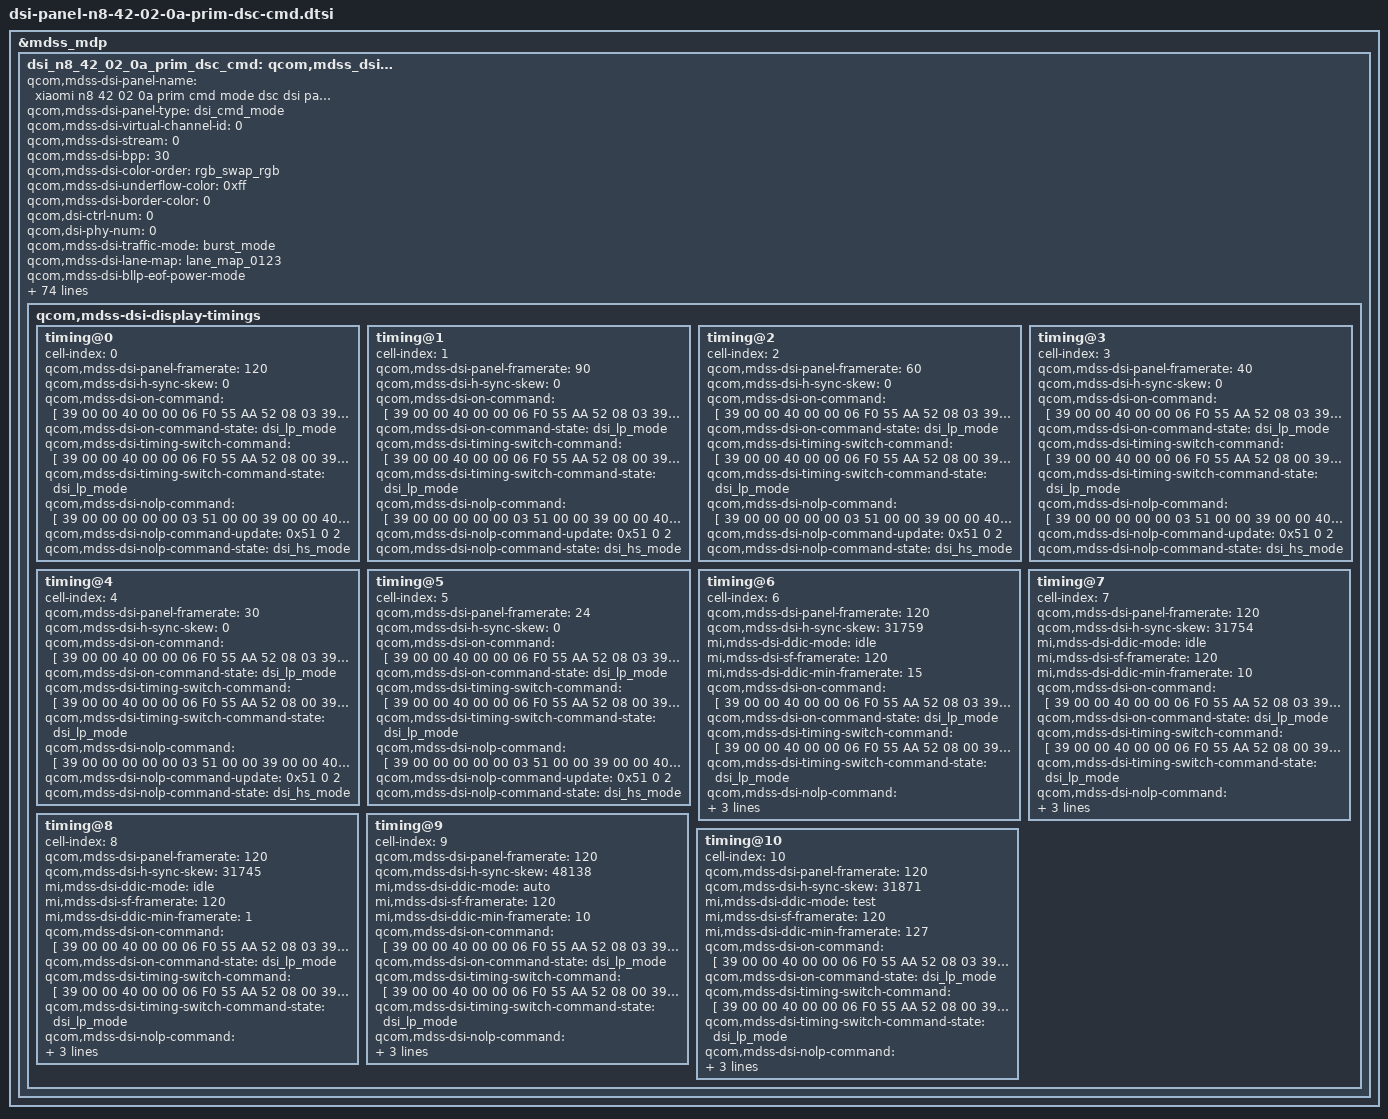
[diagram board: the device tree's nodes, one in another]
&mdss_mdp {
	dsi_n8_42_02_0a_prim_dsc_cmd: qcom,mdss_dsi_n8_42_02_0a_prim_dsc_cmd {
		qcom,mdss-dsi-panel-name = "xiaomi n8 42 02 0a prim cmd mode dsc dsi panel";
		qcom,mdss-dsi-panel-type = "dsi_cmd_mode";
		qcom,mdss-dsi-virtual-channel-id = <0>;
		qcom,mdss-dsi-stream = <0>;
		qcom,mdss-dsi-bpp = <30>;
		qcom,mdss-dsi-color-order = "rgb_swap_rgb";
		qcom,mdss-dsi-underflow-color = <0xff>;
		qcom,mdss-dsi-border-color = <0>;
		qcom,dsi-ctrl-num = <0>;
		qcom,dsi-phy-num = <0>;

		qcom,mdss-dsi-traffic-mode = "burst_mode";
		qcom,mdss-dsi-lane-map = "lane_map_0123";
		qcom,mdss-dsi-bllp-eof-power-mode;
		qcom,mdss-dsi-bllp-power-mode;
		qcom,mdss-dsi-lane-0-state;
		qcom,mdss-dsi-lane-1-state;
		qcom,mdss-dsi-lane-2-state;
		qcom,mdss-dsi-lane-3-state;
		qcom,mdss-dsi-dma-trigger = "trigger_sw";
		qcom,mdss-dsi-mdp-trigger = "none";
		qcom,mdss-dsi-reset-sequence = <1 1>, <0 1>, <1 10>;
		qcom,mdss-pan-physical-width-dimension = <675>;
		qcom,mdss-pan-physical-height-dimension = <1606>;
		qcom,mdss-dsi-te-pin-select = <1>;
		qcom,mdss-dsi-wr-mem-start = <0x2c>;
		qcom,mdss-dsi-wr-mem-continue = <0x3c>;
		qcom,mdss-dsi-te-dcs-command = <1>;
		qcom,mdss-dsi-te-check-enable;
		qcom,mdss-dsi-te-using-te-pin;
		qcom,mdss-dsi-tx-eot-append;
		qcom,mdss-dsi-lp11-init;

		qcom,mdss-dsi-bl-inverted-dbv;
		qcom,bl-update-flag = "delay_until_first_frame";

		qcom,mdss-dsi-panel-hdr-enabled;
		qcom,mdss-dsi-panel-hdr-color-primaries = <14500 15500 32000
			17000 15500 30000 8000 3000>;
		qcom,mdss-dsi-panel-peak-brightness = <4200000>;
		qcom,mdss-dsi-panel-blackness-level = <3230>;

		qcom,mdss-dsi-dma-schedule-line = <1>;
		qcom,mdss-dsi-dma-schedule-window = <50>;

		/* IRQF_ONESHOT | IRQF_TRIGGER_HEIGH */
		mi,esd-err-irq-gpio = <&tlmm 92 0x2004>;
		//qcom,spr-pack-type = "pentile";

		mi,panel-id = <0x00004E38 0x5042020A>;

		mi,ddic-round-corner-enabled;

		mi,flat-need-sync-te;
		mi,flatmode-default-on-enabled;

		mi,flatmode-status-check-enabled;
		mi,mdss-dsi-panel-flatmode-status-command = [
			06 01 00 01 00 00 01 5F
		];
		mi,mdss-dsi-panel-flatmode-status-command-state = "dsi_hs_mode";
		mi,mdss-dsi-panel-flatmode-status-read-length = <1>;
		mi,mdss-dsi-panel-flatmode-on-status-value = <0x00>;

		mi,mdss-dsi-panel-wp-read-command = [06 01 00 01 00 00 01 A3];
		mi,mdss-dsi-panel-wp-read-command-state = "dsi_hs_mode";
		mi,mdss-dsi-panel-wp-read-length = <8>;
		/* esd-check reg_read */
		//qcom,esd-check-enabled;
		//qcom,esd-aod-check-enabled;
		//mi,mdss-dsi-panel-status-check-interval = <1000>;
		//qcom,mdss-dsi-panel-status-check-mode = "reg_read";
		//mi,mdss-dsi-panel-status-offset-command = [39 00 00 00 00 00 03 FF 5A 82
		//					      39 00 00 00 00 00 02 65 01];
		//qcom,mdss-dsi-panel-status-command = [06 01 00 00 00 00 01 F9];
		//mi,mdss-dsi-panel-status-after-command = [39 00 00 00 00 00 03 FF 5A 00];
		//qcom,mdss-dsi-panel-status-command-state = "dsi_lp_mode";
		//mi,mdss-dsi-panel-status-offset-command-state = "dsi_lp_mode";
		//mi,mdss-dsi-panel-status-after-command-state = "dsi_lp_mode";
		//qcom,mdss-dsi-panel-status-value = <0x08>;
		//qcom,mdss-dsi-panel-status-read-length = <1>;

		mi,panel-on-dimming-delay = <120>;
		mi,max-brightness-clone = <16383>;

		mi,mdss-dsi-fac-bl-max-level = <11467>;
		mi,mdss-fac-brightness-max-level = <11467>;
		mi,doze-hbm-dbv-level = <1311>;
		mi,doze-lbm-dbv-level = <80>;

		qcom,mdss-dsi-display-timings {
			timing@0 {
				#include "dsi-panel-n8-42-02-0a-prim-dsc-cmd-common.dtsi"
				cell-index = <0>;
				qcom,mdss-dsi-panel-framerate = <120>;
				qcom,mdss-dsi-h-sync-skew = <0>;

				qcom,mdss-dsi-on-command = [
					/* Low frame switch skip 120 TE */
					39 00 00 40 00 00 06 F0 55 AA 52 08 03
					39 00 00 40 00 00 02 6F 0B
					39 00 00 00 00 00 02 C6 06
					/*IDLE 1*/
					39 00 00 40 00 00 06 F0 55 AA 52 08 00
					39 00 00 40 00 00 02 6F A4
					39 00 00 40 00 00 11 BA 03 03 03 06 01 01 01 06 00 01 01 14 00 00 01 16
					39 00 00 40 00 00 02 6F 1C
					39 00 00 40 00 00 11 BA 01 01 01 01 00 00 00 00 01 01 01 01 00 00 00 00
					39 00 00 40 00 00 02 6F 2C
					39 00 00 40 00 00 11 BA 01 01 01 01 01 01 01 01 01 01 01 01 00 00 00 00
					39 00 00 40 00 00 02 6F 3C
					39 00 00 40 00 00 11 BA 01 01 01 01 03 03 03 03 01 01 01 01 00 00 00 00
					39 00 00 40 00 00 02 6F 4C
					39 00 00 40 00 00 11 BA 01 01 01 01 0B 0B 04 0B 01 01 01 01 00 00 00 00
					/*thermal compensation DBI on*/
					39 00 00 40 00 00 06 F0 55 AA 52 08 08
					39 00 00 40 00 00 03 C2 22 80
					39 00 00 40 00 00 02 C7 13
					39 00 00 40 00 00 13 CB 00 00 00 00 00 00 00 00 00 00 00 00 00 00 00 00 00 00
					39 00 00 40 00 00 13 CC 00 00 00 00 00 00 00 00 00 00 00 00 00 00 00 00 00 00
					39 00 00 40 00 00 13 CE 00 00 00 00 00 00 00 00 00 00 00 00 00 00 00 00 00 00
					39 00 00 40 00 00 03 D3 80 01
					39 00 00 40 00 00 02 6F 02
					39 00 00 40 00 00 06 D3 10 00 98 00 6B
					39 00 00 00 00 00 05 67 80 40 80 80
					/*on ddic corner*/
					39 00 00 40 00 00 06 F0 55 AA 52 08 07
					39 00 00 40 00 00 02 6F 03
					39 00 00 40 00 00 05 C0 00 00 00 00
					39 00 00 40 00 00 16 C1 30 0F 02 71 09 61 F6 6E 3F FD BA F2 3F F9 AE 9E 00 00 89 54 40
					39 00 00 40 00 00 02 6F 15
					39 00 00 40 00 00 11 C1 0F 00 37 AF 00 00 19 37 F0 E7 89 0B 9F 30 FF 00
					39 00 00 40 00 00 02 6F 25
					39 00 00 40 00 00 08 C1 00 2F 37 00 10 18 00
					39 00 00 40 00 00 16 C2 30 0F 27 10 00 64 F8 30 3F FA AA 38 3F FF 84 90 00 00 27 10 00
					39 00 00 40 00 00 02 6F 15
					39 00 00 40 00 00 11 C2 03 00 00 0A 00 56 F6 B3 F0 62 F6 06 2C C0 00 FE
					39 00 00 40 00 00 02 6F 25
					39 00 00 40 00 00 08 C2 00 01 09 00 4F 56 00
					39 00 00 00 00 00 16 C3 30 0F 01 69 01 21 FD 7A 3F FE 6A 5A 3F FE C1 F2 00 00 3C C7 39
					39 00 00 40 00 00 02 6F 15
					39 00 00 40 00 00 11 C3 0C 00 0A 36 00 19 55 44 F0 C5 D5 09 E9 F0 FF FF
					39 00 00 40 00 00 02 6F 25
					39 00 00 40 00 00 08 C3 44 91 99 00 10 18 00
					39 00 00 40 00 00 16 C4 3C 00 2F 44 00 64 08 98 3F F5 0A 60 00 00 00 00 00 00 00 00 00
					39 00 00 40 00 00 02 6F 15
					39 00 00 40 00 00 11 C4 99 00 00 0A AB 69 09 B3 C0 62 0A 00 00 00 00 00
					39 00 00 40 00 00 02 6F 25
					39 00 00 40 00 00 08 C4 44 BF C7 00 4F 57 00
					39 00 00 40 00 00 16 C5 3C 00 01 69 01 21 02 86 3F FD D5 78 00 00 B8 D8 00 00 02 2B F1
					39 00 00 40 00 00 02 6F 15
					39 00 00 40 00 00 11 C5 2E 00 0A 36 BB 0A 46 44 C0 C5 2B 00 00 30 FF 00
					39 00 00 40 00 00 02 6F 25
					39 00 00 40 00 00 08 C5 00 2F 37 BB 47 4F 00
					39 00 00 00 00 00 16 C6 3C 00 02 71 0B 64 0A 8C 3F FC 9A DC 00 04 C0 CC 00 00 03 67 95
					39 00 00 40 00 00 02 6F 15
					39 00 00 40 00 00 11 C6 09 00 37 B4 BB 46 5F 37 C0 E7 7C 00 00 30 FF 00
					39 00 00 40 00 00 02 6F 25
					39 00 00 00 00 00 08 C6 00 01 09 BB 07 0F 00
					39 00 00 40 00 00 16 C7 31 00 06 E4 06 E4 00 00 3F FD BD 30 3F FD BD 30 00 00 34 0E 78
					39 00 00 40 00 00 02 6F 15
					39 00 00 40 00 00 11 C7 0C 22 38 63 00 23 4E 44 F0 D6 D6 06 E4 F0 FF FF
					39 00 00 40 00 00 02 6F 25
					39 00 00 40 00 00 08 C7 44 91 99 BB 47 4F 00
					39 00 00 40 00 00 16 C8 3D 00 06 E4 06 E4 00 00 3F FD BD 30 00 00 00 00 00 00 02 49 B4
					39 00 00 40 00 00 02 6F 15
					39 00 00 00 00 00 11 C8 1D 22 38 63 00 4F 7A 44 C0 D6 2A 00 00 30 FF 00
					39 00 00 40 00 00 02 6F 25
					39 00 00 40 00 00 08 C8 44 BF C7 BB 07 0F 00
					39 00 00 40 00 00 0F D1 80 00 00 00 00 04 C7 80 00 01 94 B0 04 C7
					39 00 00 40 00 00 02 6F 0E
					39 00 00 40 00 00 0F D1 80 00 01 AB B1 04 C7 FF FF A4 DE 50 04 C7
					39 00 00 40 00 00 02 6F 1C
					39 00 00 40 00 00 0F D1 FF FF AD 0A 89 04 C7 FF FE ED A5 A0 04 C7
					39 00 00 40 00 00 02 6F 2A
					39 00 00 40 00 00 0C D1 80 00 02 49 B4 04 C7 FF FF D0 84
					39 00 00 00 00 00 12 D2 F0 04 C7 00 00 00 00 00 00 00 00 00 00 00 00 00 00
					//ESD DECTED
					39 00 00 40 00 00 06 F0 55 AA 52 08 00
					39 00 00 40 00 00 03 BE 47 45
					//normal low,active high
					39 00 00 40 00 00 02 6F 05
					39 00 00 40 00 00 02 BE 28
					39 00 00 40 00 00 02 6F 19
					39 00 00 40 00 00 05 BE 10 91 00 AB
					//VESA_PPS_DT_BLOCK_SLO_DISPON=1
					39 00 00 40 00 00 02 6F 0D
					39 00 00 40 00 00 02 D8 42
					//AUTO ENABLE
					39 00 00 40 00 00 06 F0 55 AA 52 08 00
					39 00 00 40 00 00 02 6F D9
					39 00 00 40 00 00 02 BA 00
					//DVDD enhance
					39 00 00 40 00 00 06 F0 55 AA 52 08 01
					39 00 00 40 00 00 02 6F 05
					39 00 00 40 00 00 04 C5 00 00 00
					//EM pulse multi to one optimize
					39 00 00 40 00 00 02 E5 00
					//VINITN2 bias adjust
					39 00 00 40 00 00 05 FF AA 55 A5 80
					39 00 00 40 00 00 02 6F 32
					39 00 00 40 00 00 02 F9 00
					//AOD WB timing optimize
					39 00 00 40 00 00 05 FF AA 55 A5 81
					39 00 00 40 00 00 02 6F 02
					39 00 00 40 00 00 02 F9 84
					//AOD SOP optimize
					39 00 00 40 00 00 05 FF AA 55 A5 81
					39 00 00 40 00 00 02 6F 13
					39 00 00 40 00 00 02 F9 00
					//Enalbe fskip_extend vfp function
					39 00 00 40 00 00 05 FF AA 55 A5 81
					39 00 00 40 00 00 02 6F 0C
					39 00 00 40 00 00 02 FD 08
					//Frameskip Chopper timing adjust
					39 00 00 40 00 00 05 FF AA 55 A5 81
					39 00 00 40 00 00 02 6F 10
					39 00 00 40 00 00 02 FB 40
					//Disable VOLTP output for power saving
					39 00 00 40 00 00 05 FF AA 55 A5 80
					39 00 00 40 00 00 02 6F 42
					39 00 00 40 00 00 02 F4 00
					39 00 00 40 00 00 02 6F 49
					39 00 00 00 00 00 02 F2 10
					/*video trim*/
					39 00 00 40 00 00 06 F0 55 AA 52 08 01
					39 00 00 40 00 00 2A C3 DD 06 20 11 FF 00 06 20 11 FF 00 06 29 1F 06 51 19 06 29 1F 06 51 19 06 29 1F 06 51 19 06 29 1F 06 51 19 06 29 1F 06 51 19
					/*VESA optimize*/
					39 00 00 40 00 00 06 F0 55 AA 52 08 00
					39 00 00 40 00 00 02 E0 1C
					39 00 00 40 00 00 05 FF AA 55 A5 80
					39 00 00 40 00 00 02 6F 31
					39 00 00 00 00 00 03 F8 01 8E
					39 00 00 40 00 00 05 FF AA 55 A5 80
					39 00 00 40 00 00 02 6F 15
					39 00 00 40 00 00 03 F8 01 8D
					39 00 00 40 00 00 02 6F 16
					39 00 00 40 00 00 03 F4 02 74
					39 00 00 40 00 00 05 FF AA 55 A5 81
					39 00 00 40 00 00 02 6F 05
					39 00 00 40 00 00 03 FE 3C 3C
					39 00 00 40 00 00 02 6F 0D
					39 00 00 00 00 00 02 FB 80
					39 00 00 40 00 00 05 FF AA 55 A5 80
					39 00 00 40 00 00 02 6F 0A
					39 00 00 40 00 00 06 F6 70 70 70 70 70
					39 00 00 40 00 00 02 17 30
					//Source optimize
					39 00 00 40 00 00 05 FF AA 55 A5 80
					39 00 00 40 00 00 02 6F 2A
					39 00 00 40 00 00 02 F4 08
					//MIPI RX driving optimize
					39 00 00 40 00 00 05 FF AA 55 A5 82
					39 00 00 40 00 00 02 6F 09
					39 00 00 40 00 00 02 F2 FF
					39 00 00 40 00 00 06 F0 55 AA 52 08 01
					39 00 00 40 00 00 02 6F 06
					39 00 00 40 00 00 03 C5 0A 0A
					//close cmd2 cmd3
					39 00 00 40 00 00 06 F0 55 AA 52 00 00
					39 00 00 40 00 00 05 FF AA 55 A5 00
					39 00 00 40 00 00 05 2A 00 00 04 C7
					39 00 00 40 00 00 05 2B 00 00 0B 5F
					39 00 00 40 00 00 02 90 03
					39 00 00 40 00 00 02 6F 01
					39 00 00 40 00 00 02 90 43
					39 00 00 40 00 00 13 91 AB A8 00 20 C2 00 02 32 03 47 00 08 03 19 02 CE 10 F0
					39 00 00 40 00 00 02 6F 06
					39 00 00 40 00 00 02 6D 00
					39 00 00 40 00 00 02 6D 00
					39 00 00 40 00 00 02 2F 30
					/*gir on*/
					39 00 00 40 00 00 02 5F 00
					39 00 00 40 00 00 02 35 00
					39 00 00 40 00 00 03 51 00 00
					39 00 00 40 00 00 02 53 20
					39 00 00 00 00 00 02 26 00
					39 00 00 00 00 00 02 5A 00
					39 00 00 40 00 00 02 6F 03
					39 00 00 40 00 00 03 35 00 00
					/* Display On */
					05 00 00 00 78 00 01 11
					05 00 00 00 00 00 01 29
				];
				qcom,mdss-dsi-on-command-state = "dsi_lp_mode";

				qcom,mdss-dsi-timing-switch-command = [
					/* Auto Dimming OFF */
					/*Frame skip OFF (Auto Mode)*/
					/*Frame Skip Mode 1*/
					39 00 00 40 00 00 06 F0 55 AA 52 08 00
					//AUTO ENABLE
					39 00 00 40 00 00 02 6F D9
					39 00 00 40 00 00 02 BA 00
					//OPT_fskip_abort_event OFF
					/*backlight off the back fun*/
					39 00 00 40 00 00 02 6F 08
					39 00 00 40 00 00 02 B2 80
					//close cmd2
					39 00 00 40 00 00 06 F0 55 AA 52 00 00
					/* Frequency Select 120Hz */
					39 00 00 40 00 00 02 6F 03
					39 00 00 40 00 00 03 35 00 00
					39 00 00 00 00 00 02 6D 00
				];

				qcom,mdss-dsi-timing-switch-command-state = "dsi_lp_mode";

				qcom,mdss-dsi-nolp-command = [
					39 00 00 00 00 00 03 51 00 00
					/* Aod Mode Off */
					39 00 00 40 00 00 02 38 00
					/*back to normal te*/
					39 00 00 40 00 00 02 6F 03
					39 00 00 00 00 00 03 35 00 00
				];
				qcom,mdss-dsi-nolp-command-update = <0x51 0 2>;
				qcom,mdss-dsi-nolp-command-state = "dsi_hs_mode";
			};
			timing@1 {
				#include "dsi-panel-n8-42-02-0a-prim-dsc-cmd-common.dtsi"
				cell-index = <1>;
				qcom,mdss-dsi-panel-framerate = <90>;
				qcom,mdss-dsi-h-sync-skew = <0>;

				qcom,mdss-dsi-on-command = [
					/* Low frame switch skip 120 TE */
					39 00 00 40 00 00 06 F0 55 AA 52 08 03
					39 00 00 40 00 00 02 6F 0B
					39 00 00 00 00 00 02 C6 06
					/*IDLE 1*/
					39 00 00 40 00 00 06 F0 55 AA 52 08 00
					39 00 00 40 00 00 02 6F A4
					39 00 00 40 00 00 11 BA 03 03 03 06 01 01 01 06 00 01 01 14 00 00 01 16
					39 00 00 40 00 00 02 6F 1C
					39 00 00 40 00 00 11 BA 01 01 01 01 00 00 00 00 01 01 01 01 00 00 00 00
					39 00 00 40 00 00 02 6F 2C
					39 00 00 40 00 00 11 BA 01 01 01 01 01 01 01 01 01 01 01 01 00 00 00 00
					39 00 00 40 00 00 02 6F 3C
					39 00 00 40 00 00 11 BA 01 01 01 01 03 03 03 03 01 01 01 01 00 00 00 00
					39 00 00 40 00 00 02 6F 4C
					39 00 00 40 00 00 11 BA 01 01 01 01 0B 0B 04 0B 01 01 01 01 00 00 00 00
					/*thermal compensation DBI on*/
					39 00 00 40 00 00 06 F0 55 AA 52 08 08
					39 00 00 40 00 00 03 C2 22 80
					39 00 00 40 00 00 02 C7 13
					39 00 00 40 00 00 13 CB 00 00 00 00 00 00 00 00 00 00 00 00 00 00 00 00 00 00
					39 00 00 40 00 00 13 CC 00 00 00 00 00 00 00 00 00 00 00 00 00 00 00 00 00 00
					39 00 00 40 00 00 13 CE 00 00 00 00 00 00 00 00 00 00 00 00 00 00 00 00 00 00
					39 00 00 40 00 00 03 D3 80 01
					39 00 00 40 00 00 02 6F 02
					39 00 00 40 00 00 06 D3 10 00 98 00 6B
					39 00 00 00 00 00 05 67 80 40 80 80
					/*on ddic corner*/
					39 00 00 40 00 00 06 F0 55 AA 52 08 07
					39 00 00 40 00 00 02 6F 03
					39 00 00 40 00 00 05 C0 00 00 00 00
					39 00 00 40 00 00 16 C1 30 0F 02 71 09 61 F6 6E 3F FD BA F2 3F F9 AE 9E 00 00 89 54 40
					39 00 00 40 00 00 02 6F 15
					39 00 00 40 00 00 11 C1 0F 00 37 AF 00 00 19 37 F0 E7 89 0B 9F 30 FF 00
					39 00 00 40 00 00 02 6F 25
					39 00 00 40 00 00 08 C1 00 2F 37 00 10 18 00
					39 00 00 40 00 00 16 C2 30 0F 27 10 00 64 F8 30 3F FA AA 38 3F FF 84 90 00 00 27 10 00
					39 00 00 40 00 00 02 6F 15
					39 00 00 40 00 00 11 C2 03 00 00 0A 00 56 F6 B3 F0 62 F6 06 2C C0 00 FE
					39 00 00 40 00 00 02 6F 25
					39 00 00 40 00 00 08 C2 00 01 09 00 4F 56 00
					39 00 00 00 00 00 16 C3 30 0F 01 69 01 21 FD 7A 3F FE 6A 5A 3F FE C1 F2 00 00 3C C7 39
					39 00 00 40 00 00 02 6F 15
					39 00 00 40 00 00 11 C3 0C 00 0A 36 00 19 55 44 F0 C5 D5 09 E9 F0 FF FF
					39 00 00 40 00 00 02 6F 25
					39 00 00 40 00 00 08 C3 44 91 99 00 10 18 00
					39 00 00 40 00 00 16 C4 3C 00 2F 44 00 64 08 98 3F F5 0A 60 00 00 00 00 00 00 00 00 00
					39 00 00 40 00 00 02 6F 15
					39 00 00 40 00 00 11 C4 99 00 00 0A AB 69 09 B3 C0 62 0A 00 00 00 00 00
					39 00 00 40 00 00 02 6F 25
					39 00 00 40 00 00 08 C4 44 BF C7 00 4F 57 00
					39 00 00 40 00 00 16 C5 3C 00 01 69 01 21 02 86 3F FD D5 78 00 00 B8 D8 00 00 02 2B F1
					39 00 00 40 00 00 02 6F 15
					39 00 00 40 00 00 11 C5 2E 00 0A 36 BB 0A 46 44 C0 C5 2B 00 00 30 FF 00
					39 00 00 40 00 00 02 6F 25
					39 00 00 40 00 00 08 C5 00 2F 37 BB 47 4F 00
					39 00 00 00 00 00 16 C6 3C 00 02 71 0B 64 0A 8C 3F FC 9A DC 00 04 C0 CC 00 00 03 67 95
					39 00 00 40 00 00 02 6F 15
					39 00 00 40 00 00 11 C6 09 00 37 B4 BB 46 5F 37 C0 E7 7C 00 00 30 FF 00
					39 00 00 40 00 00 02 6F 25
					39 00 00 00 00 00 08 C6 00 01 09 BB 07 0F 00
					39 00 00 40 00 00 16 C7 31 00 06 E4 06 E4 00 00 3F FD BD 30 3F FD BD 30 00 00 34 0E 78
					39 00 00 40 00 00 02 6F 15
					39 00 00 40 00 00 11 C7 0C 22 38 63 00 23 4E 44 F0 D6 D6 06 E4 F0 FF FF
					39 00 00 40 00 00 02 6F 25
					39 00 00 40 00 00 08 C7 44 91 99 BB 47 4F 00
					39 00 00 40 00 00 16 C8 3D 00 06 E4 06 E4 00 00 3F FD BD 30 00 00 00 00 00 00 02 49 B4
					39 00 00 40 00 00 02 6F 15
					39 00 00 00 00 00 11 C8 1D 22 38 63 00 4F 7A 44 C0 D6 2A 00 00 30 FF 00
					39 00 00 40 00 00 02 6F 25
					39 00 00 40 00 00 08 C8 44 BF C7 BB 07 0F 00
					39 00 00 40 00 00 0F D1 80 00 00 00 00 04 C7 80 00 01 94 B0 04 C7
					39 00 00 40 00 00 02 6F 0E
					39 00 00 40 00 00 0F D1 80 00 01 AB B1 04 C7 FF FF A4 DE 50 04 C7
					39 00 00 40 00 00 02 6F 1C
					39 00 00 40 00 00 0F D1 FF FF AD 0A 89 04 C7 FF FE ED A5 A0 04 C7
					39 00 00 40 00 00 02 6F 2A
					39 00 00 40 00 00 0C D1 80 00 02 49 B4 04 C7 FF FF D0 84
					39 00 00 00 00 00 12 D2 F0 04 C7 00 00 00 00 00 00 00 00 00 00 00 00 00 00
					//ESD DECTED
					39 00 00 40 00 00 06 F0 55 AA 52 08 00
					39 00 00 40 00 00 03 BE 47 45
					//normal low,active high
					39 00 00 40 00 00 02 6F 05
					39 00 00 40 00 00 02 BE 28
					39 00 00 40 00 00 02 6F 19
					39 00 00 40 00 00 05 BE 10 91 00 AB
					//VESA_PPS_DT_BLOCK_SLO_DISPON=1
					39 00 00 40 00 00 02 6F 0D
					39 00 00 40 00 00 02 D8 42
					//AUTO ENABLE
					39 00 00 40 00 00 06 F0 55 AA 52 08 00
					39 00 00 40 00 00 02 6F D9
					39 00 00 40 00 00 02 BA 00
					//DVDD enhance
					39 00 00 40 00 00 06 F0 55 AA 52 08 01
					39 00 00 40 00 00 02 6F 05
					39 00 00 40 00 00 04 C5 00 00 00
					//EM pulse multi to one optimize
					39 00 00 40 00 00 02 E5 00
					//VINITN2 bias adjust
					39 00 00 40 00 00 05 FF AA 55 A5 80
					39 00 00 40 00 00 02 6F 32
					39 00 00 40 00 00 02 F9 00
					//AOD WB timing optimize
					39 00 00 40 00 00 05 FF AA 55 A5 81
					39 00 00 40 00 00 02 6F 02
					39 00 00 40 00 00 02 F9 84
					//AOD SOP optimize
					39 00 00 40 00 00 05 FF AA 55 A5 81
					39 00 00 40 00 00 02 6F 13
					39 00 00 40 00 00 02 F9 00
					//Enalbe fskip_extend vfp function
					39 00 00 40 00 00 05 FF AA 55 A5 81
					39 00 00 40 00 00 02 6F 0C
					39 00 00 40 00 00 02 FD 08
					//Frameskip Chopper timing adjust
					39 00 00 40 00 00 05 FF AA 55 A5 81
					39 00 00 40 00 00 02 6F 10
					39 00 00 40 00 00 02 FB 40
					//Disable VOLTP output for power saving
					39 00 00 40 00 00 05 FF AA 55 A5 80
					39 00 00 40 00 00 02 6F 42
					39 00 00 40 00 00 02 F4 00
					39 00 00 40 00 00 02 6F 49
					39 00 00 00 00 00 02 F2 10
					/*video trim*/
					39 00 00 40 00 00 06 F0 55 AA 52 08 01
					39 00 00 40 00 00 2A C3 DD 06 20 11 FF 00 06 20 11 FF 00 06 29 1F 06 51 19 06 29 1F 06 51 19 06 29 1F 06 51 19 06 29 1F 06 51 19 06 29 1F 06 51 19
					/*VESA optimize*/
					39 00 00 40 00 00 06 F0 55 AA 52 08 00
					39 00 00 40 00 00 02 E0 1C
					39 00 00 40 00 00 05 FF AA 55 A5 80
					39 00 00 40 00 00 02 6F 31
					39 00 00 00 00 00 03 F8 01 8E
					39 00 00 40 00 00 05 FF AA 55 A5 80
					39 00 00 40 00 00 02 6F 15
					39 00 00 40 00 00 03 F8 01 8D
					39 00 00 40 00 00 02 6F 16
					39 00 00 40 00 00 03 F4 02 74
					39 00 00 40 00 00 05 FF AA 55 A5 81
					39 00 00 40 00 00 02 6F 05
					39 00 00 40 00 00 03 FE 3C 3C
					39 00 00 40 00 00 02 6F 0D
					39 00 00 00 00 00 02 FB 80
					39 00 00 40 00 00 05 FF AA 55 A5 80
					39 00 00 40 00 00 02 6F 0A
					39 00 00 40 00 00 06 F6 70 70 70 70 70
					39 00 00 40 00 00 02 17 30
					//Source optimize
					39 00 00 40 00 00 05 FF AA 55 A5 80
					39 00 00 40 00 00 02 6F 2A
					39 00 00 40 00 00 02 F4 08
					//MIPI RX driving optimize
					39 00 00 40 00 00 05 FF AA 55 A5 82
					39 00 00 40 00 00 02 6F 09
					39 00 00 40 00 00 02 F2 FF
					39 00 00 40 00 00 06 F0 55 AA 52 08 01
					39 00 00 40 00 00 02 6F 06
					39 00 00 40 00 00 03 C5 0A 0A
					//close cmd2 cmd3
					39 00 00 40 00 00 06 F0 55 AA 52 00 00
					39 00 00 40 00 00 05 FF AA 55 A5 00
					39 00 00 40 00 00 05 2A 00 00 04 C7
					39 00 00 40 00 00 05 2B 00 00 0B 5F
					39 00 00 40 00 00 02 90 03
					39 00 00 40 00 00 02 6F 01
					39 00 00 40 00 00 02 90 43
					39 00 00 40 00 00 13 91 AB A8 00 20 C2 00 02 32 03 47 00 08 03 19 02 CE 10 F0
					39 00 00 40 00 00 02 6F 06
					39 00 00 40 00 00 02 6D 00
					39 00 00 40 00 00 02 6D 01
					39 00 00 40 00 00 02 2F 31
					/*gir on*/
					39 00 00 40 00 00 02 5F 00
					39 00 00 40 00 00 02 35 00
					39 00 00 40 00 00 03 51 00 00
					39 00 00 40 00 00 02 53 20
					39 00 00 00 00 00 02 26 00
					39 00 00 00 00 00 02 5A 00
					39 00 00 40 00 00 02 6F 03
					39 00 00 40 00 00 03 35 00 00
					/* Display On */
					05 00 00 00 78 00 01 11
					05 00 00 00 00 00 01 29
				];
				qcom,mdss-dsi-on-command-state = "dsi_lp_mode";

				qcom,mdss-dsi-timing-switch-command = [
					/* Auto Dimming OFF */
					/*Frame skip OFF (Auto Mode)*/
					/*Frame Skip Mode 1*/
					39 00 00 40 00 00 06 F0 55 AA 52 08 00
					//AUTO ENABLE
					39 00 00 40 00 00 02 6F D9
					39 00 00 40 00 00 02 BA 00
					//OPT_fskip_abort_event OFF
					/*backlight off the back fun*/
					39 00 00 40 00 00 02 6F 08
					39 00 00 40 00 00 02 B2 80
					//close cmd2
					39 00 00 40 00 00 06 F0 55 AA 52 00 00
					/* Frequency Select 90Hz */
					39 00 00 40 00 00 02 6F 03
					39 00 00 40 00 00 03 35 00 00
					39 00 00 00 00 00 02 6D 01
				];

				qcom,mdss-dsi-timing-switch-command-state = "dsi_lp_mode";

				qcom,mdss-dsi-nolp-command = [
					39 00 00 00 00 00 03 51 00 00
					/* Aod Mode Off */
					39 00 00 40 00 00 02 38 00
					/*back to normal te*/
					39 00 00 40 00 00 02 6F 03
					39 00 00 00 00 00 03 35 00 00
				];
				qcom,mdss-dsi-nolp-command-update = <0x51 0 2>;
				qcom,mdss-dsi-nolp-command-state = "dsi_hs_mode";
			};
			timing@2 {
				#include "dsi-panel-n8-42-02-0a-prim-dsc-cmd-common.dtsi"
				cell-index = <2>;
				qcom,mdss-dsi-panel-framerate = <60>;
				qcom,mdss-dsi-h-sync-skew = <0>;

				qcom,mdss-dsi-on-command = [
					/* Low frame switch skip 120 TE */
					39 00 00 40 00 00 06 F0 55 AA 52 08 03
					39 00 00 40 00 00 02 6F 0B
					39 00 00 00 00 00 02 C6 06
					/*IDLE 1*/
					39 00 00 40 00 00 06 F0 55 AA 52 08 00
					39 00 00 40 00 00 02 6F A4
					39 00 00 40 00 00 11 BA 03 03 03 06 01 01 01 06 00 01 01 14 00 00 01 16
					39 00 00 40 00 00 02 6F 1C
					39 00 00 40 00 00 11 BA 01 01 01 01 00 00 00 00 01 01 01 01 00 00 00 00
					39 00 00 40 00 00 02 6F 2C
					39 00 00 40 00 00 11 BA 01 01 01 01 01 01 01 01 01 01 01 01 00 00 00 00
					39 00 00 40 00 00 02 6F 3C
					39 00 00 40 00 00 11 BA 01 01 01 01 03 03 03 03 01 01 01 01 00 00 00 00
					39 00 00 40 00 00 02 6F 4C
					39 00 00 40 00 00 11 BA 01 01 01 01 0B 0B 04 0B 01 01 01 01 00 00 00 00
					/*thermal compensation DBI on*/
					39 00 00 40 00 00 06 F0 55 AA 52 08 08
					39 00 00 40 00 00 03 C2 22 80
					39 00 00 40 00 00 02 C7 13
					39 00 00 40 00 00 13 CB 00 00 00 00 00 00 00 00 00 00 00 00 00 00 00 00 00 00
					39 00 00 40 00 00 13 CC 00 00 00 00 00 00 00 00 00 00 00 00 00 00 00 00 00 00
					39 00 00 40 00 00 13 CE 00 00 00 00 00 00 00 00 00 00 00 00 00 00 00 00 00 00
					39 00 00 40 00 00 03 D3 80 01
					39 00 00 40 00 00 02 6F 02
					39 00 00 40 00 00 06 D3 10 00 98 00 6B
					39 00 00 00 00 00 05 67 80 40 80 80
					/*on ddic corner*/
					39 00 00 40 00 00 06 F0 55 AA 52 08 07
					39 00 00 40 00 00 02 6F 03
					39 00 00 40 00 00 05 C0 00 00 00 00
					39 00 00 40 00 00 16 C1 30 0F 02 71 09 61 F6 6E 3F FD BA F2 3F F9 AE 9E 00 00 89 54 40
					39 00 00 40 00 00 02 6F 15
					39 00 00 40 00 00 11 C1 0F 00 37 AF 00 00 19 37 F0 E7 89 0B 9F 30 FF 00
					39 00 00 40 00 00 02 6F 25
					39 00 00 40 00 00 08 C1 00 2F 37 00 10 18 00
					39 00 00 40 00 00 16 C2 30 0F 27 10 00 64 F8 30 3F FA AA 38 3F FF 84 90 00 00 27 10 00
					39 00 00 40 00 00 02 6F 15
					39 00 00 40 00 00 11 C2 03 00 00 0A 00 56 F6 B3 F0 62 F6 06 2C C0 00 FE
					39 00 00 40 00 00 02 6F 25
					39 00 00 40 00 00 08 C2 00 01 09 00 4F 56 00
					39 00 00 00 00 00 16 C3 30 0F 01 69 01 21 FD 7A 3F FE 6A 5A 3F FE C1 F2 00 00 3C C7 39
					39 00 00 40 00 00 02 6F 15
					39 00 00 40 00 00 11 C3 0C 00 0A 36 00 19 55 44 F0 C5 D5 09 E9 F0 FF FF
					39 00 00 40 00 00 02 6F 25
					39 00 00 40 00 00 08 C3 44 91 99 00 10 18 00
					39 00 00 40 00 00 16 C4 3C 00 2F 44 00 64 08 98 3F F5 0A 60 00 00 00 00 00 00 00 00 00
					39 00 00 40 00 00 02 6F 15
					39 00 00 40 00 00 11 C4 99 00 00 0A AB 69 09 B3 C0 62 0A 00 00 00 00 00
					39 00 00 40 00 00 02 6F 25
					39 00 00 40 00 00 08 C4 44 BF C7 00 4F 57 00
					39 00 00 40 00 00 16 C5 3C 00 01 69 01 21 02 86 3F FD D5 78 00 00 B8 D8 00 00 02 2B F1
					39 00 00 40 00 00 02 6F 15
					39 00 00 40 00 00 11 C5 2E 00 0A 36 BB 0A 46 44 C0 C5 2B 00 00 30 FF 00
					39 00 00 40 00 00 02 6F 25
					39 00 00 40 00 00 08 C5 00 2F 37 BB 47 4F 00
					39 00 00 00 00 00 16 C6 3C 00 02 71 0B 64 0A 8C 3F FC 9A DC 00 04 C0 CC 00 00 03 67 95
					39 00 00 40 00 00 02 6F 15
					39 00 00 40 00 00 11 C6 09 00 37 B4 BB 46 5F 37 C0 E7 7C 00 00 30 FF 00
					39 00 00 40 00 00 02 6F 25
					39 00 00 00 00 00 08 C6 00 01 09 BB 07 0F 00
					39 00 00 40 00 00 16 C7 31 00 06 E4 06 E4 00 00 3F FD BD 30 3F FD BD 30 00 00 34 0E 78
					39 00 00 40 00 00 02 6F 15
					39 00 00 40 00 00 11 C7 0C 22 38 63 00 23 4E 44 F0 D6 D6 06 E4 F0 FF FF
					39 00 00 40 00 00 02 6F 25
					39 00 00 40 00 00 08 C7 44 91 99 BB 47 4F 00
					39 00 00 40 00 00 16 C8 3D 00 06 E4 06 E4 00 00 3F FD BD 30 00 00 00 00 00 00 02 49 B4
					39 00 00 40 00 00 02 6F 15
					39 00 00 00 00 00 11 C8 1D 22 38 63 00 4F 7A 44 C0 D6 2A 00 00 30 FF 00
					39 00 00 40 00 00 02 6F 25
					39 00 00 40 00 00 08 C8 44 BF C7 BB 07 0F 00
					39 00 00 40 00 00 0F D1 80 00 00 00 00 04 C7 80 00 01 94 B0 04 C7
					39 00 00 40 00 00 02 6F 0E
					39 00 00 40 00 00 0F D1 80 00 01 AB B1 04 C7 FF FF A4 DE 50 04 C7
					39 00 00 40 00 00 02 6F 1C
					39 00 00 40 00 00 0F D1 FF FF AD 0A 89 04 C7 FF FE ED A5 A0 04 C7
					39 00 00 40 00 00 02 6F 2A
					39 00 00 40 00 00 0C D1 80 00 02 49 B4 04 C7 FF FF D0 84
					39 00 00 00 00 00 12 D2 F0 04 C7 00 00 00 00 00 00 00 00 00 00 00 00 00 00
					//ESD DECTED
					39 00 00 40 00 00 06 F0 55 AA 52 08 00
					39 00 00 40 00 00 03 BE 47 45
					//normal low,active high
					39 00 00 40 00 00 02 6F 05
					39 00 00 40 00 00 02 BE 28
					39 00 00 40 00 00 02 6F 19
					39 00 00 40 00 00 05 BE 10 91 00 AB
					//VESA_PPS_DT_BLOCK_SLO_DISPON=1
					39 00 00 40 00 00 02 6F 0D
					39 00 00 40 00 00 02 D8 42
					//AUTO OFF
					39 00 00 40 00 00 06 F0 55 AA 52 08 00
					39 00 00 40 00 00 02 6F D9
					39 00 00 40 00 00 02 BA 04
					//DVDD enhance
					39 00 00 40 00 00 06 F0 55 AA 52 08 01
					39 00 00 40 00 00 02 6F 05
					39 00 00 40 00 00 04 C5 00 00 00
					//EM pulse multi to one optimize
					39 00 00 40 00 00 02 E5 00
					//VINITN2 bias adjust
					39 00 00 40 00 00 05 FF AA 55 A5 80
					39 00 00 40 00 00 02 6F 32
					39 00 00 40 00 00 02 F9 00
					//AOD WB timing optimize
					39 00 00 40 00 00 05 FF AA 55 A5 81
					39 00 00 40 00 00 02 6F 02
					39 00 00 40 00 00 02 F9 84
					//AOD SOP optimize
					39 00 00 40 00 00 05 FF AA 55 A5 81
					39 00 00 40 00 00 02 6F 13
					39 00 00 40 00 00 02 F9 00
					//Enalbe fskip_extend vfp function
					39 00 00 40 00 00 05 FF AA 55 A5 81
					39 00 00 40 00 00 02 6F 0C
					39 00 00 40 00 00 02 FD 08
					//Frameskip Chopper timing adjust
					39 00 00 40 00 00 05 FF AA 55 A5 81
					39 00 00 40 00 00 02 6F 10
					39 00 00 40 00 00 02 FB 40
					//Disable VOLTP output for power saving
					39 00 00 40 00 00 05 FF AA 55 A5 80
					39 00 00 40 00 00 02 6F 42
					39 00 00 40 00 00 02 F4 00
					39 00 00 40 00 00 02 6F 49
					39 00 00 00 00 00 02 F2 10
					/*video trim*/
					39 00 00 40 00 00 06 F0 55 AA 52 08 01
					39 00 00 40 00 00 2A C3 DD 06 20 11 FF 00 06 20 11 FF 00 06 29 1F 06 51 19 06 29 1F 06 51 19 06 29 1F 06 51 19 06 29 1F 06 51 19 06 29 1F 06 51 19
					/*VESA optimize*/
					39 00 00 40 00 00 06 F0 55 AA 52 08 00
					39 00 00 40 00 00 02 E0 1C
					39 00 00 40 00 00 05 FF AA 55 A5 80
					39 00 00 40 00 00 02 6F 31
					39 00 00 00 00 00 03 F8 01 8E
					39 00 00 40 00 00 05 FF AA 55 A5 80
					39 00 00 40 00 00 02 6F 15
					39 00 00 40 00 00 03 F8 01 8D
					39 00 00 40 00 00 02 6F 16
					39 00 00 40 00 00 03 F4 02 74
					39 00 00 40 00 00 05 FF AA 55 A5 81
					39 00 00 40 00 00 02 6F 05
					39 00 00 40 00 00 03 FE 3C 3C
					39 00 00 40 00 00 02 6F 0D
					39 00 00 00 00 00 02 FB 80
					39 00 00 40 00 00 05 FF AA 55 A5 80
					39 00 00 40 00 00 02 6F 0A
					39 00 00 40 00 00 06 F6 70 70 70 70 70
					39 00 00 40 00 00 02 17 30
					//Source optimize
					39 00 00 40 00 00 05 FF AA 55 A5 80
					39 00 00 40 00 00 02 6F 2A
					39 00 00 40 00 00 02 F4 08
					//MIPI RX driving optimize
					39 00 00 40 00 00 05 FF AA 55 A5 82
					39 00 00 40 00 00 02 6F 09
					39 00 00 40 00 00 02 F2 FF
					39 00 00 40 00 00 06 F0 55 AA 52 08 01
					39 00 00 40 00 00 02 6F 06
					39 00 00 40 00 00 03 C5 0A 0A
					//close cmd2 cmd3
					39 00 00 40 00 00 06 F0 55 AA 52 00 00
					39 00 00 40 00 00 05 FF AA 55 A5 00
					39 00 00 40 00 00 05 2A 00 00 04 C7
					39 00 00 40 00 00 05 2B 00 00 0B 5F
					39 00 00 40 00 00 02 90 03
					39 00 00 40 00 00 02 6F 01
					39 00 00 40 00 00 02 90 43
					39 00 00 40 00 00 13 91 AB A8 00 20 C2 00 02 32 03 47 00 08 03 19 02 CE 10 F0
					39 00 00 40 00 00 02 6F 06
					39 00 00 40 00 00 02 6D 00
					/*60hz*/
					39 00 00 40 00 00 02 6D 02
					39 00 00 40 00 00 02 2F 30
					/*gir on*/
					39 00 00 40 00 00 02 5F 00
					39 00 00 40 00 00 02 35 00
					39 00 00 40 00 00 03 51 00 00
					39 00 00 40 00 00 02 53 20
					39 00 00 00 00 00 02 26 00
					39 00 00 00 00 00 02 5A 00
					39 00 00 40 00 00 02 6F 03
					39 00 00 40 00 00 03 35 00 01
					/* Display On */
					05 00 00 00 78 00 01 11
					05 00 00 00 00 00 01 29
				];
				qcom,mdss-dsi-on-command-state = "dsi_lp_mode";

				qcom,mdss-dsi-timing-switch-command = [
					/* Auto Dimming OFF */
					/*Frame skip OFF (Auto Mode)*/
					/*Frame Skip Mode 1*/
					39 00 00 40 00 00 06 F0 55 AA 52 08 00
					//AUTO OFF
					39 00 00 40 00 00 02 6F D9
					39 00 00 40 00 00 02 BA 04
					//OPT_fskip_abort_event OFF
					/*backlight off the back fun*/
					39 00 00 40 00 00 02 6F 08
					39 00 00 40 00 00 02 B2 80
					//close cmd2
					39 00 00 40 00 00 06 F0 55 AA 52 00 00
					/* Frequency Select 60Hz */
					39 00 00 40 00 00 02 6F 03
					39 00 00 40 00 00 03 35 00 01
					39 00 00 00 00 00 02 6D 02
				];

				qcom,mdss-dsi-timing-switch-command-state = "dsi_lp_mode";

				qcom,mdss-dsi-nolp-command = [
					39 00 00 00 00 00 03 51 00 00
					/* Aod Mode Off */
					39 00 00 40 00 00 02 38 00
					/*back to normal te*/
					39 00 00 40 00 00 02 6F 03
					39 00 00 00 00 00 03 35 00 01
				];
				qcom,mdss-dsi-nolp-command-update = <0x51 0 2>;
				qcom,mdss-dsi-nolp-command-state = "dsi_hs_mode";
			};
			timing@3 {
				#include "dsi-panel-n8-42-02-0a-prim-dsc-cmd-common.dtsi"
				cell-index = <3>;
				qcom,mdss-dsi-panel-framerate = <40>;
				qcom,mdss-dsi-h-sync-skew = <0>;

				qcom,mdss-dsi-on-command = [
					/* Low frame switch skip 120 TE */
					39 00 00 40 00 00 06 F0 55 AA 52 08 03
					39 00 00 40 00 00 02 6F 0B
					39 00 00 00 00 00 02 C6 06
					/*IDLE 1*/
					39 00 00 40 00 00 06 F0 55 AA 52 08 00
					39 00 00 40 00 00 02 6F A4
					39 00 00 40 00 00 11 BA 03 03 03 06 01 01 01 06 00 01 01 14 00 00 01 16
					39 00 00 40 00 00 02 6F 1C
					39 00 00 40 00 00 11 BA 01 01 01 01 00 00 00 00 01 01 01 01 00 00 00 00
					39 00 00 40 00 00 02 6F 2C
					39 00 00 40 00 00 11 BA 01 01 01 01 01 01 01 01 01 01 01 01 00 00 00 00
					39 00 00 40 00 00 02 6F 3C
					39 00 00 40 00 00 11 BA 01 01 01 01 03 03 03 03 01 01 01 01 00 00 00 00
					39 00 00 40 00 00 02 6F 4C
					39 00 00 40 00 00 11 BA 01 01 01 01 0B 0B 04 0B 01 01 01 01 00 00 00 00
					/*thermal compensation DBI on*/
					39 00 00 40 00 00 06 F0 55 AA 52 08 08
					39 00 00 40 00 00 03 C2 22 80
					39 00 00 40 00 00 02 C7 13
					39 00 00 40 00 00 13 CB 00 00 00 00 00 00 00 00 00 00 00 00 00 00 00 00 00 00
					39 00 00 40 00 00 13 CC 00 00 00 00 00 00 00 00 00 00 00 00 00 00 00 00 00 00
					39 00 00 40 00 00 13 CE 00 00 00 00 00 00 00 00 00 00 00 00 00 00 00 00 00 00
					39 00 00 40 00 00 03 D3 80 01
					39 00 00 40 00 00 02 6F 02
					39 00 00 40 00 00 06 D3 10 00 98 00 6B
					39 00 00 00 00 00 05 67 80 40 80 80
					/*on ddic corner*/
					39 00 00 40 00 00 06 F0 55 AA 52 08 07
					39 00 00 40 00 00 02 6F 03
					39 00 00 40 00 00 05 C0 00 00 00 00
					39 00 00 40 00 00 16 C1 30 0F 02 71 09 61 F6 6E 3F FD BA F2 3F F9 AE 9E 00 00 89 54 40
					39 00 00 40 00 00 02 6F 15
					39 00 00 40 00 00 11 C1 0F 00 37 AF 00 00 19 37 F0 E7 89 0B 9F 30 FF 00
					39 00 00 40 00 00 02 6F 25
					39 00 00 40 00 00 08 C1 00 2F 37 00 10 18 00
					39 00 00 40 00 00 16 C2 30 0F 27 10 00 64 F8 30 3F FA AA 38 3F FF 84 90 00 00 27 10 00
					39 00 00 40 00 00 02 6F 15
					39 00 00 40 00 00 11 C2 03 00 00 0A 00 56 F6 B3 F0 62 F6 06 2C C0 00 FE
					39 00 00 40 00 00 02 6F 25
					39 00 00 40 00 00 08 C2 00 01 09 00 4F 56 00
					39 00 00 00 00 00 16 C3 30 0F 01 69 01 21 FD 7A 3F FE 6A 5A 3F FE C1 F2 00 00 3C C7 39
					39 00 00 40 00 00 02 6F 15
					39 00 00 40 00 00 11 C3 0C 00 0A 36 00 19 55 44 F0 C5 D5 09 E9 F0 FF FF
					39 00 00 40 00 00 02 6F 25
					39 00 00 40 00 00 08 C3 44 91 99 00 10 18 00
					39 00 00 40 00 00 16 C4 3C 00 2F 44 00 64 08 98 3F F5 0A 60 00 00 00 00 00 00 00 00 00
					39 00 00 40 00 00 02 6F 15
					39 00 00 40 00 00 11 C4 99 00 00 0A AB 69 09 B3 C0 62 0A 00 00 00 00 00
					39 00 00 40 00 00 02 6F 25
					39 00 00 40 00 00 08 C4 44 BF C7 00 4F 57 00
					39 00 00 40 00 00 16 C5 3C 00 01 69 01 21 02 86 3F FD D5 78 00 00 B8 D8 00 00 02 2B F1
					39 00 00 40 00 00 02 6F 15
					39 00 00 40 00 00 11 C5 2E 00 0A 36 BB 0A 46 44 C0 C5 2B 00 00 30 FF 00
					39 00 00 40 00 00 02 6F 25
					39 00 00 40 00 00 08 C5 00 2F 37 BB 47 4F 00
					39 00 00 00 00 00 16 C6 3C 00 02 71 0B 64 0A 8C 3F FC 9A DC 00 04 C0 CC 00 00 03 67 95
					39 00 00 40 00 00 02 6F 15
					39 00 00 40 00 00 11 C6 09 00 37 B4 BB 46 5F 37 C0 E7 7C 00 00 30 FF 00
					39 00 00 40 00 00 02 6F 25
					39 00 00 00 00 00 08 C6 00 01 09 BB 07 0F 00
					39 00 00 40 00 00 16 C7 31 00 06 E4 06 E4 00 00 3F FD BD 30 3F FD BD 30 00 00 34 0E 78
					39 00 00 40 00 00 02 6F 15
					39 00 00 40 00 00 11 C7 0C 22 38 63 00 23 4E 44 F0 D6 D6 06 E4 F0 FF FF
					39 00 00 40 00 00 02 6F 25
					39 00 00 40 00 00 08 C7 44 91 99 BB 47 4F 00
					39 00 00 40 00 00 16 C8 3D 00 06 E4 06 E4 00 00 3F FD BD 30 00 00 00 00 00 00 02 49 B4
					39 00 00 40 00 00 02 6F 15
					39 00 00 00 00 00 11 C8 1D 22 38 63 00 4F 7A 44 C0 D6 2A 00 00 30 FF 00
					39 00 00 40 00 00 02 6F 25
					39 00 00 40 00 00 08 C8 44 BF C7 BB 07 0F 00
					39 00 00 40 00 00 0F D1 80 00 00 00 00 04 C7 80 00 01 94 B0 04 C7
					39 00 00 40 00 00 02 6F 0E
					39 00 00 40 00 00 0F D1 80 00 01 AB B1 04 C7 FF FF A4 DE 50 04 C7
					39 00 00 40 00 00 02 6F 1C
					39 00 00 40 00 00 0F D1 FF FF AD 0A 89 04 C7 FF FE ED A5 A0 04 C7
					39 00 00 40 00 00 02 6F 2A
					39 00 00 40 00 00 0C D1 80 00 02 49 B4 04 C7 FF FF D0 84
					39 00 00 00 00 00 12 D2 F0 04 C7 00 00 00 00 00 00 00 00 00 00 00 00 00 00
					//ESD DECTED
					39 00 00 40 00 00 06 F0 55 AA 52 08 00
					39 00 00 40 00 00 03 BE 47 45
					//normal low,active high
					39 00 00 40 00 00 02 6F 05
					39 00 00 40 00 00 02 BE 28
					39 00 00 40 00 00 02 6F 19
					39 00 00 40 00 00 05 BE 10 91 00 AB
					//VESA_PPS_DT_BLOCK_SLO_DISPON=1
					39 00 00 40 00 00 02 6F 0D
					39 00 00 40 00 00 02 D8 42
					//AUTO OFF
					39 00 00 40 00 00 06 F0 55 AA 52 08 00
					39 00 00 40 00 00 02 6F D9
					39 00 00 40 00 00 02 BA 04
					//DVDD enhance
					39 00 00 40 00 00 06 F0 55 AA 52 08 01
					39 00 00 40 00 00 02 6F 05
					39 00 00 40 00 00 04 C5 00 00 00
					//EM pulse multi to one optimize
					39 00 00 40 00 00 02 E5 00
					//VINITN2 bias adjust
					39 00 00 40 00 00 05 FF AA 55 A5 80
					39 00 00 40 00 00 02 6F 32
					39 00 00 40 00 00 02 F9 00
					//AOD WB timing optimize
					39 00 00 40 00 00 05 FF AA 55 A5 81
					39 00 00 40 00 00 02 6F 02
					39 00 00 40 00 00 02 F9 84
					//AOD SOP optimize
					39 00 00 40 00 00 05 FF AA 55 A5 81
					39 00 00 40 00 00 02 6F 13
					39 00 00 40 00 00 02 F9 00
					//Enalbe fskip_extend vfp function
					39 00 00 40 00 00 05 FF AA 55 A5 81
					39 00 00 40 00 00 02 6F 0C
					39 00 00 40 00 00 02 FD 08
					//Frameskip Chopper timing adjust
					39 00 00 40 00 00 05 FF AA 55 A5 81
					39 00 00 40 00 00 02 6F 10
					39 00 00 40 00 00 02 FB 40
					//Disable VOLTP output for power saving
					39 00 00 40 00 00 05 FF AA 55 A5 80
					39 00 00 40 00 00 02 6F 42
					39 00 00 40 00 00 02 F4 00
					39 00 00 40 00 00 02 6F 49
					39 00 00 00 00 00 02 F2 10
					/*video trim*/
					39 00 00 40 00 00 06 F0 55 AA 52 08 01
					39 00 00 40 00 00 2A C3 DD 06 20 11 FF 00 06 20 11 FF 00 06 29 1F 06 51 19 06 29 1F 06 51 19 06 29 1F 06 51 19 06 29 1F 06 51 19 06 29 1F 06 51 19
					/*VESA optimize*/
					39 00 00 40 00 00 06 F0 55 AA 52 08 00
					39 00 00 40 00 00 02 E0 1C
					39 00 00 40 00 00 05 FF AA 55 A5 80
					39 00 00 40 00 00 02 6F 31
					39 00 00 00 00 00 03 F8 01 8E
					39 00 00 40 00 00 05 FF AA 55 A5 80
					39 00 00 40 00 00 02 6F 15
					39 00 00 40 00 00 03 F8 01 8D
					39 00 00 40 00 00 02 6F 16
					39 00 00 40 00 00 03 F4 02 74
					39 00 00 40 00 00 05 FF AA 55 A5 81
					39 00 00 40 00 00 02 6F 05
					39 00 00 40 00 00 03 FE 3C 3C
					39 00 00 40 00 00 02 6F 0D
					39 00 00 00 00 00 02 FB 80
					39 00 00 40 00 00 05 FF AA 55 A5 80
					39 00 00 40 00 00 02 6F 0A
					39 00 00 40 00 00 06 F6 70 70 70 70 70
					39 00 00 40 00 00 02 17 30
					//Source optimize
					39 00 00 40 00 00 05 FF AA 55 A5 80
					39 00 00 40 00 00 02 6F 2A
					39 00 00 40 00 00 02 F4 08
					//MIPI RX driving optimize
					39 00 00 40 00 00 05 FF AA 55 A5 82
					39 00 00 40 00 00 02 6F 09
					39 00 00 40 00 00 02 F2 FF
					39 00 00 40 00 00 06 F0 55 AA 52 08 01
					39 00 00 40 00 00 02 6F 06
					39 00 00 40 00 00 03 C5 0A 0A
					//close cmd2 cmd3
					39 00 00 40 00 00 06 F0 55 AA 52 00 00
					39 00 00 40 00 00 05 FF AA 55 A5 00
					39 00 00 40 00 00 05 2A 00 00 04 C7
					39 00 00 40 00 00 05 2B 00 00 0B 5F
					39 00 00 40 00 00 02 90 03
					39 00 00 40 00 00 02 6F 01
					39 00 00 40 00 00 02 90 43
					39 00 00 40 00 00 13 91 AB A8 00 20 C2 00 02 32 03 47 00 08 03 19 02 CE 10 F0
					39 00 00 40 00 00 02 6F 06
					39 00 00 40 00 00 02 6D 00
					/*40hz*/
					39 00 00 40 00 00 02 6D 03
					39 00 00 40 00 00 02 2F 30
					/*gir on*/
					39 00 00 40 00 00 02 5F 00
					39 00 00 40 00 00 02 35 00
					39 00 00 40 00 00 03 51 00 00
					39 00 00 40 00 00 02 53 20
					39 00 00 00 00 00 02 26 00
					39 00 00 00 00 00 02 5A 00
					39 00 00 40 00 00 02 6F 03
					39 00 00 40 00 00 03 35 00 02
					/* Display On */
					05 00 00 00 78 00 01 11
					05 00 00 00 00 00 01 29
				];
				qcom,mdss-dsi-on-command-state = "dsi_lp_mode";

				qcom,mdss-dsi-timing-switch-command = [
					/* Auto Dimming OFF */
					/*Frame skip OFF (Auto Mode)*/
					/*Frame Skip Mode 1*/
					39 00 00 40 00 00 06 F0 55 AA 52 08 00
					//AUTO OFF
					39 00 00 40 00 00 02 6F D9
					39 00 00 40 00 00 02 BA 04
					//OPT_fskip_abort_event OFF
					/*backlight off the back fun*/
					39 00 00 40 00 00 02 6F 08
					39 00 00 40 00 00 02 B2 80
					//close cmd2
					39 00 00 40 00 00 06 F0 55 AA 52 00 00
					/* Frequency Select 40Hz */
					39 00 00 40 00 00 02 6F 03
					39 00 00 40 00 00 03 35 00 02
					39 00 00 00 00 00 02 6D 03
				];

				qcom,mdss-dsi-timing-switch-command-state = "dsi_lp_mode";

				qcom,mdss-dsi-nolp-command = [
					39 00 00 00 00 00 03 51 00 00
					/* Aod Mode Off */
					39 00 00 40 00 00 02 38 00
					/*back to normal te*/
					39 00 00 40 00 00 02 6F 03
					39 00 00 00 00 00 03 35 00 02
				];
				qcom,mdss-dsi-nolp-command-update = <0x51 0 2>;
				qcom,mdss-dsi-nolp-command-state = "dsi_hs_mode";
			};
			timing@4 {
				#include "dsi-panel-n8-42-02-0a-prim-dsc-cmd-common.dtsi"
				cell-index = <4>;
				qcom,mdss-dsi-panel-framerate = <30>;
				qcom,mdss-dsi-h-sync-skew = <0>;

				qcom,mdss-dsi-on-command = [
					/* Low frame switch skip 120 TE */
					39 00 00 40 00 00 06 F0 55 AA 52 08 03
					39 00 00 40 00 00 02 6F 0B
					39 00 00 00 00 00 02 C6 06
					/*IDLE 1*/
					39 00 00 40 00 00 06 F0 55 AA 52 08 00
					39 00 00 40 00 00 02 6F A4
					39 00 00 40 00 00 11 BA 03 03 03 06 01 01 01 06 00 01 01 14 00 00 01 16
					39 00 00 40 00 00 02 6F 1C
					39 00 00 40 00 00 11 BA 01 01 01 01 00 00 00 00 01 01 01 01 00 00 00 00
					39 00 00 40 00 00 02 6F 2C
					39 00 00 40 00 00 11 BA 01 01 01 01 01 01 01 01 01 01 01 01 00 00 00 00
					39 00 00 40 00 00 02 6F 3C
					39 00 00 40 00 00 11 BA 01 01 01 01 03 03 03 03 01 01 01 01 00 00 00 00
					39 00 00 40 00 00 02 6F 4C
					39 00 00 40 00 00 11 BA 01 01 01 01 0B 0B 04 0B 01 01 01 01 00 00 00 00
					/*thermal compensation DBI on*/
					39 00 00 40 00 00 06 F0 55 AA 52 08 08
					39 00 00 40 00 00 03 C2 22 80
					39 00 00 40 00 00 02 C7 13
					39 00 00 40 00 00 13 CB 00 00 00 00 00 00 00 00 00 00 00 00 00 00 00 00 00 00
					39 00 00 40 00 00 13 CC 00 00 00 00 00 00 00 00 00 00 00 00 00 00 00 00 00 00
					39 00 00 40 00 00 13 CE 00 00 00 00 00 00 00 00 00 00 00 00 00 00 00 00 00 00
					39 00 00 40 00 00 03 D3 80 01
					39 00 00 40 00 00 02 6F 02
					39 00 00 40 00 00 06 D3 10 00 98 00 6B
					39 00 00 00 00 00 05 67 80 40 80 80
					/*on ddic corner*/
					39 00 00 40 00 00 06 F0 55 AA 52 08 07
					39 00 00 40 00 00 02 6F 03
					39 00 00 40 00 00 05 C0 00 00 00 00
					39 00 00 40 00 00 16 C1 30 0F 02 71 09 61 F6 6E 3F FD BA F2 3F F9 AE 9E 00 00 89 54 40
					39 00 00 40 00 00 02 6F 15
					39 00 00 40 00 00 11 C1 0F 00 37 AF 00 00 19 37 F0 E7 89 0B 9F 30 FF 00
					39 00 00 40 00 00 02 6F 25
					39 00 00 40 00 00 08 C1 00 2F 37 00 10 18 00
					39 00 00 40 00 00 16 C2 30 0F 27 10 00 64 F8 30 3F FA AA 38 3F FF 84 90 00 00 27 10 00
					39 00 00 40 00 00 02 6F 15
					39 00 00 40 00 00 11 C2 03 00 00 0A 00 56 F6 B3 F0 62 F6 06 2C C0 00 FE
					39 00 00 40 00 00 02 6F 25
					39 00 00 40 00 00 08 C2 00 01 09 00 4F 56 00
					39 00 00 00 00 00 16 C3 30 0F 01 69 01 21 FD 7A 3F FE 6A 5A 3F FE C1 F2 00 00 3C C7 39
					39 00 00 40 00 00 02 6F 15
					39 00 00 40 00 00 11 C3 0C 00 0A 36 00 19 55 44 F0 C5 D5 09 E9 F0 FF FF
					39 00 00 40 00 00 02 6F 25
					39 00 00 40 00 00 08 C3 44 91 99 00 10 18 00
					39 00 00 40 00 00 16 C4 3C 00 2F 44 00 64 08 98 3F F5 0A 60 00 00 00 00 00 00 00 00 00
					39 00 00 40 00 00 02 6F 15
					39 00 00 40 00 00 11 C4 99 00 00 0A AB 69 09 B3 C0 62 0A 00 00 00 00 00
					39 00 00 40 00 00 02 6F 25
					39 00 00 40 00 00 08 C4 44 BF C7 00 4F 57 00
					39 00 00 40 00 00 16 C5 3C 00 01 69 01 21 02 86 3F FD D5 78 00 00 B8 D8 00 00 02 2B F1
					39 00 00 40 00 00 02 6F 15
					39 00 00 40 00 00 11 C5 2E 00 0A 36 BB 0A 46 44 C0 C5 2B 00 00 30 FF 00
					39 00 00 40 00 00 02 6F 25
					39 00 00 40 00 00 08 C5 00 2F 37 BB 47 4F 00
					39 00 00 00 00 00 16 C6 3C 00 02 71 0B 64 0A 8C 3F FC 9A DC 00 04 C0 CC 00 00 03 67 95
					39 00 00 40 00 00 02 6F 15
					39 00 00 40 00 00 11 C6 09 00 37 B4 BB 46 5F 37 C0 E7 7C 00 00 30 FF 00
					39 00 00 40 00 00 02 6F 25
					39 00 00 00 00 00 08 C6 00 01 09 BB 07 0F 00
					39 00 00 40 00 00 16 C7 31 00 06 E4 06 E4 00 00 3F FD BD 30 3F FD BD 30 00 00 34 0E 78
					39 00 00 40 00 00 02 6F 15
					39 00 00 40 00 00 11 C7 0C 22 38 63 00 23 4E 44 F0 D6 D6 06 E4 F0 FF FF
					39 00 00 40 00 00 02 6F 25
					39 00 00 40 00 00 08 C7 44 91 99 BB 47 4F 00
					39 00 00 40 00 00 16 C8 3D 00 06 E4 06 E4 00 00 3F FD BD 30 00 00 00 00 00 00 02 49 B4
					39 00 00 40 00 00 02 6F 15
					39 00 00 00 00 00 11 C8 1D 22 38 63 00 4F 7A 44 C0 D6 2A 00 00 30 FF 00
					39 00 00 40 00 00 02 6F 25
					39 00 00 40 00 00 08 C8 44 BF C7 BB 07 0F 00
					39 00 00 40 00 00 0F D1 80 00 00 00 00 04 C7 80 00 01 94 B0 04 C7
					39 00 00 40 00 00 02 6F 0E
					39 00 00 40 00 00 0F D1 80 00 01 AB B1 04 C7 FF FF A4 DE 50 04 C7
					39 00 00 40 00 00 02 6F 1C
					39 00 00 40 00 00 0F D1 FF FF AD 0A 89 04 C7 FF FE ED A5 A0 04 C7
					39 00 00 40 00 00 02 6F 2A
					39 00 00 40 00 00 0C D1 80 00 02 49 B4 04 C7 FF FF D0 84
					39 00 00 00 00 00 12 D2 F0 04 C7 00 00 00 00 00 00 00 00 00 00 00 00 00 00
					//ESD DECTED
					39 00 00 40 00 00 06 F0 55 AA 52 08 00
					39 00 00 40 00 00 03 BE 47 45
					//normal low,active high
					39 00 00 40 00 00 02 6F 05
					39 00 00 40 00 00 02 BE 28
					39 00 00 40 00 00 02 6F 19
					39 00 00 40 00 00 05 BE 10 91 00 AB
					//VESA_PPS_DT_BLOCK_SLO_DISPON=1
					39 00 00 40 00 00 02 6F 0D
					39 00 00 40 00 00 02 D8 42
					//AUTO OFF
					39 00 00 40 00 00 06 F0 55 AA 52 08 00
					39 00 00 40 00 00 02 6F D9
					39 00 00 40 00 00 02 BA 04
					//DVDD enhance
					39 00 00 40 00 00 06 F0 55 AA 52 08 01
					39 00 00 40 00 00 02 6F 05
					39 00 00 40 00 00 04 C5 00 00 00
					//EM pulse multi to one optimize
					39 00 00 40 00 00 02 E5 00
					//VINITN2 bias adjust
					39 00 00 40 00 00 05 FF AA 55 A5 80
					39 00 00 40 00 00 02 6F 32
					39 00 00 40 00 00 02 F9 00
					//AOD WB timing optimize
					39 00 00 40 00 00 05 FF AA 55 A5 81
					39 00 00 40 00 00 02 6F 02
					39 00 00 40 00 00 02 F9 84
					//AOD SOP optimize
					39 00 00 40 00 00 05 FF AA 55 A5 81
					39 00 00 40 00 00 02 6F 13
					39 00 00 40 00 00 02 F9 00
					//Enalbe fskip_extend vfp function
					39 00 00 40 00 00 05 FF AA 55 A5 81
					39 00 00 40 00 00 02 6F 0C
					39 00 00 40 00 00 02 FD 08
					//Frameskip Chopper timing adjust
					39 00 00 40 00 00 05 FF AA 55 A5 81
					39 00 00 40 00 00 02 6F 10
					39 00 00 40 00 00 02 FB 40
					//Disable VOLTP output for power saving
					39 00 00 40 00 00 05 FF AA 55 A5 80
					39 00 00 40 00 00 02 6F 42
					39 00 00 40 00 00 02 F4 00
					39 00 00 40 00 00 02 6F 49
					39 00 00 00 00 00 02 F2 10
					/*video trim*/
					39 00 00 40 00 00 06 F0 55 AA 52 08 01
					39 00 00 40 00 00 2A C3 DD 06 20 11 FF 00 06 20 11 FF 00 06 29 1F 06 51 19 06 29 1F 06 51 19 06 29 1F 06 51 19 06 29 1F 06 51 19 06 29 1F 06 51 19
					/*VESA optimize*/
					39 00 00 40 00 00 06 F0 55 AA 52 08 00
					39 00 00 40 00 00 02 E0 1C
					39 00 00 40 00 00 05 FF AA 55 A5 80
					39 00 00 40 00 00 02 6F 31
					39 00 00 00 00 00 03 F8 01 8E
					39 00 00 40 00 00 05 FF AA 55 A5 80
					39 00 00 40 00 00 02 6F 15
					39 00 00 40 00 00 03 F8 01 8D
					39 00 00 40 00 00 02 6F 16
					39 00 00 40 00 00 03 F4 02 74
					39 00 00 40 00 00 05 FF AA 55 A5 81
					39 00 00 40 00 00 02 6F 05
					39 00 00 40 00 00 03 FE 3C 3C
					39 00 00 40 00 00 02 6F 0D
					39 00 00 00 00 00 02 FB 80
					39 00 00 40 00 00 05 FF AA 55 A5 80
					39 00 00 40 00 00 02 6F 0A
					39 00 00 40 00 00 06 F6 70 70 70 70 70
					39 00 00 40 00 00 02 17 30
					//Source optimize
					39 00 00 40 00 00 05 FF AA 55 A5 80
					39 00 00 40 00 00 02 6F 2A
					39 00 00 40 00 00 02 F4 08
					//MIPI RX driving optimize
					39 00 00 40 00 00 05 FF AA 55 A5 82
					39 00 00 40 00 00 02 6F 09
					39 00 00 40 00 00 02 F2 FF
					39 00 00 40 00 00 06 F0 55 AA 52 08 01
					39 00 00 40 00 00 02 6F 06
					39 00 00 40 00 00 03 C5 0A 0A
					//close cmd2 cmd3
					39 00 00 40 00 00 06 F0 55 AA 52 00 00
					39 00 00 40 00 00 05 FF AA 55 A5 00
					39 00 00 40 00 00 05 2A 00 00 04 C7
					39 00 00 40 00 00 05 2B 00 00 0B 5F
					39 00 00 40 00 00 02 90 03
					39 00 00 40 00 00 02 6F 01
					39 00 00 40 00 00 02 90 43
					39 00 00 40 00 00 13 91 AB A8 00 20 C2 00 02 32 03 47 00 08 03 19 02 CE 10 F0
					39 00 00 40 00 00 02 6F 06
					39 00 00 40 00 00 02 6D 00
					/*30hz*/
					39 00 00 40 00 00 02 6D 04
					39 00 00 40 00 00 02 2F 30
					/*gir on*/
					39 00 00 40 00 00 02 5F 00
					39 00 00 40 00 00 02 35 00
					39 00 00 40 00 00 03 51 00 00
					39 00 00 40 00 00 02 53 20
					39 00 00 00 00 00 02 26 00
					39 00 00 00 00 00 02 5A 00
					39 00 00 40 00 00 02 6F 03
					39 00 00 40 00 00 03 35 00 03
					/* Display On */
					05 00 00 00 78 00 01 11
					05 00 00 00 00 00 01 29
				];
				qcom,mdss-dsi-on-command-state = "dsi_lp_mode";

				qcom,mdss-dsi-timing-switch-command = [
					/* Auto Dimming OFF */
					/*Frame skip OFF (Auto Mode)*/
					/*Frame Skip Mode 1*/
					39 00 00 40 00 00 06 F0 55 AA 52 08 00
					//AUTO OFF
					39 00 00 40 00 00 02 6F D9
					39 00 00 40 00 00 02 BA 04
					//OPT_fskip_abort_event OFF
					/*backlight off the back fun*/
					39 00 00 40 00 00 02 6F 08
					39 00 00 40 00 00 02 B2 80
					//close cmd2
					39 00 00 40 00 00 06 F0 55 AA 52 00 00
					/* Frequency Select 30Hz */
					39 00 00 40 00 00 02 6F 03
					39 00 00 40 00 00 03 35 00 03
					39 00 00 00 00 00 02 6D 04
				];

				qcom,mdss-dsi-timing-switch-command-state = "dsi_lp_mode";

				qcom,mdss-dsi-nolp-command = [
					39 00 00 00 00 00 03 51 00 00
					/* Aod Mode Off */
					39 00 00 40 00 00 02 38 00
					/*back to normal te*/
					39 00 00 40 00 00 02 6F 03
					39 00 00 00 00 00 03 35 00 03
				];
				qcom,mdss-dsi-nolp-command-update = <0x51 0 2>;
				qcom,mdss-dsi-nolp-command-state = "dsi_hs_mode";
			};
			timing@5 {
				#include "dsi-panel-n8-42-02-0a-prim-dsc-cmd-common.dtsi"
				cell-index = <5>;
				qcom,mdss-dsi-panel-framerate = <24>;
				qcom,mdss-dsi-h-sync-skew = <0>;

				qcom,mdss-dsi-on-command = [
					/* Low frame switch skip 120 TE */
					39 00 00 40 00 00 06 F0 55 AA 52 08 03
					39 00 00 40 00 00 02 6F 0B
					39 00 00 00 00 00 02 C6 06
					/*IDLE 1*/
					39 00 00 40 00 00 06 F0 55 AA 52 08 00
					39 00 00 40 00 00 02 6F A4
					39 00 00 40 00 00 11 BA 03 03 03 06 01 01 01 06 00 01 01 14 00 00 01 16
					39 00 00 40 00 00 02 6F 1C
					39 00 00 40 00 00 11 BA 01 01 01 01 00 00 00 00 01 01 01 01 00 00 00 00
					39 00 00 40 00 00 02 6F 2C
					39 00 00 40 00 00 11 BA 01 01 01 01 01 01 01 01 01 01 01 01 00 00 00 00
					39 00 00 40 00 00 02 6F 3C
					39 00 00 40 00 00 11 BA 01 01 01 01 03 03 03 03 01 01 01 01 00 00 00 00
					39 00 00 40 00 00 02 6F 4C
					39 00 00 40 00 00 11 BA 01 01 01 01 0B 0B 04 0B 01 01 01 01 00 00 00 00
					/*thermal compensation DBI on*/
					39 00 00 40 00 00 06 F0 55 AA 52 08 08
					39 00 00 40 00 00 03 C2 22 80
					39 00 00 40 00 00 02 C7 13
					39 00 00 40 00 00 13 CB 00 00 00 00 00 00 00 00 00 00 00 00 00 00 00 00 00 00
					39 00 00 40 00 00 13 CC 00 00 00 00 00 00 00 00 00 00 00 00 00 00 00 00 00 00
					39 00 00 40 00 00 13 CE 00 00 00 00 00 00 00 00 00 00 00 00 00 00 00 00 00 00
					39 00 00 40 00 00 03 D3 80 01
					39 00 00 40 00 00 02 6F 02
					39 00 00 40 00 00 06 D3 10 00 98 00 6B
					39 00 00 00 00 00 05 67 80 40 80 80
					/*on ddic corner*/
					39 00 00 40 00 00 06 F0 55 AA 52 08 07
					39 00 00 40 00 00 02 6F 03
					39 00 00 40 00 00 05 C0 00 00 00 00
					39 00 00 40 00 00 16 C1 30 0F 02 71 09 61 F6 6E 3F FD BA F2 3F F9 AE 9E 00 00 89 54 40
					39 00 00 40 00 00 02 6F 15
					39 00 00 40 00 00 11 C1 0F 00 37 AF 00 00 19 37 F0 E7 89 0B 9F 30 FF 00
					39 00 00 40 00 00 02 6F 25
					39 00 00 40 00 00 08 C1 00 2F 37 00 10 18 00
					39 00 00 40 00 00 16 C2 30 0F 27 10 00 64 F8 30 3F FA AA 38 3F FF 84 90 00 00 27 10 00
					39 00 00 40 00 00 02 6F 15
					39 00 00 40 00 00 11 C2 03 00 00 0A 00 56 F6 B3 F0 62 F6 06 2C C0 00 FE
					39 00 00 40 00 00 02 6F 25
					39 00 00 40 00 00 08 C2 00 01 09 00 4F 56 00
					39 00 00 00 00 00 16 C3 30 0F 01 69 01 21 FD 7A 3F FE 6A 5A 3F FE C1 F2 00 00 3C C7 39
					39 00 00 40 00 00 02 6F 15
					39 00 00 40 00 00 11 C3 0C 00 0A 36 00 19 55 44 F0 C5 D5 09 E9 F0 FF FF
					39 00 00 40 00 00 02 6F 25
					39 00 00 40 00 00 08 C3 44 91 99 00 10 18 00
					39 00 00 40 00 00 16 C4 3C 00 2F 44 00 64 08 98 3F F5 0A 60 00 00 00 00 00 00 00 00 00
					39 00 00 40 00 00 02 6F 15
					39 00 00 40 00 00 11 C4 99 00 00 0A AB 69 09 B3 C0 62 0A 00 00 00 00 00
					39 00 00 40 00 00 02 6F 25
					39 00 00 40 00 00 08 C4 44 BF C7 00 4F 57 00
					39 00 00 40 00 00 16 C5 3C 00 01 69 01 21 02 86 3F FD D5 78 00 00 B8 D8 00 00 02 2B F1
					39 00 00 40 00 00 02 6F 15
					39 00 00 40 00 00 11 C5 2E 00 0A 36 BB 0A 46 44 C0 C5 2B 00 00 30 FF 00
					39 00 00 40 00 00 02 6F 25
					39 00 00 40 00 00 08 C5 00 2F 37 BB 47 4F 00
					39 00 00 00 00 00 16 C6 3C 00 02 71 0B 64 0A 8C 3F FC 9A DC 00 04 C0 CC 00 00 03 67 95
					39 00 00 40 00 00 02 6F 15
					39 00 00 40 00 00 11 C6 09 00 37 B4 BB 46 5F 37 C0 E7 7C 00 00 30 FF 00
					39 00 00 40 00 00 02 6F 25
					39 00 00 00 00 00 08 C6 00 01 09 BB 07 0F 00
					39 00 00 40 00 00 16 C7 31 00 06 E4 06 E4 00 00 3F FD BD 30 3F FD BD 30 00 00 34 0E 78
					39 00 00 40 00 00 02 6F 15
					39 00 00 40 00 00 11 C7 0C 22 38 63 00 23 4E 44 F0 D6 D6 06 E4 F0 FF FF
					39 00 00 40 00 00 02 6F 25
					39 00 00 40 00 00 08 C7 44 91 99 BB 47 4F 00
					39 00 00 40 00 00 16 C8 3D 00 06 E4 06 E4 00 00 3F FD BD 30 00 00 00 00 00 00 02 49 B4
					39 00 00 40 00 00 02 6F 15
					39 00 00 00 00 00 11 C8 1D 22 38 63 00 4F 7A 44 C0 D6 2A 00 00 30 FF 00
					39 00 00 40 00 00 02 6F 25
					39 00 00 40 00 00 08 C8 44 BF C7 BB 07 0F 00
					39 00 00 40 00 00 0F D1 80 00 00 00 00 04 C7 80 00 01 94 B0 04 C7
					39 00 00 40 00 00 02 6F 0E
					39 00 00 40 00 00 0F D1 80 00 01 AB B1 04 C7 FF FF A4 DE 50 04 C7
					39 00 00 40 00 00 02 6F 1C
					39 00 00 40 00 00 0F D1 FF FF AD 0A 89 04 C7 FF FE ED A5 A0 04 C7
					39 00 00 40 00 00 02 6F 2A
					39 00 00 40 00 00 0C D1 80 00 02 49 B4 04 C7 FF FF D0 84
					39 00 00 00 00 00 12 D2 F0 04 C7 00 00 00 00 00 00 00 00 00 00 00 00 00 00
					//ESD DECTED
					39 00 00 40 00 00 06 F0 55 AA 52 08 00
					39 00 00 40 00 00 03 BE 47 45
					//normal low,active high
					39 00 00 40 00 00 02 6F 05
					39 00 00 40 00 00 02 BE 28
					39 00 00 40 00 00 02 6F 19
					39 00 00 40 00 00 05 BE 10 91 00 AB
					//VESA_PPS_DT_BLOCK_SLO_DISPON=1
					39 00 00 40 00 00 02 6F 0D
					39 00 00 40 00 00 02 D8 42
					//AUTO OFF
					39 00 00 40 00 00 06 F0 55 AA 52 08 00
					39 00 00 40 00 00 02 6F D9
					39 00 00 40 00 00 02 BA 04
					//DVDD enhance
					39 00 00 40 00 00 06 F0 55 AA 52 08 01
					39 00 00 40 00 00 02 6F 05
					39 00 00 40 00 00 04 C5 00 00 00
					//EM pulse multi to one optimize
					39 00 00 40 00 00 02 E5 00
					//VINITN2 bias adjust
					39 00 00 40 00 00 05 FF AA 55 A5 80
					39 00 00 40 00 00 02 6F 32
					39 00 00 40 00 00 02 F9 00
					//AOD WB timing optimize
					39 00 00 40 00 00 05 FF AA 55 A5 81
					39 00 00 40 00 00 02 6F 02
					39 00 00 40 00 00 02 F9 84
					//AOD SOP optimize
					39 00 00 40 00 00 05 FF AA 55 A5 81
					39 00 00 40 00 00 02 6F 13
					39 00 00 40 00 00 02 F9 00
					//Enalbe fskip_extend vfp function
					39 00 00 40 00 00 05 FF AA 55 A5 81
					39 00 00 40 00 00 02 6F 0C
					39 00 00 40 00 00 02 FD 08
					//Frameskip Chopper timing adjust
					39 00 00 40 00 00 05 FF AA 55 A5 81
					39 00 00 40 00 00 02 6F 10
					39 00 00 40 00 00 02 FB 40
					//Disable VOLTP output for power saving
					39 00 00 40 00 00 05 FF AA 55 A5 80
					39 00 00 40 00 00 02 6F 42
					39 00 00 40 00 00 02 F4 00
					39 00 00 40 00 00 02 6F 49
					39 00 00 00 00 00 02 F2 10
					/*video trim*/
					39 00 00 40 00 00 06 F0 55 AA 52 08 01
					39 00 00 40 00 00 2A C3 DD 06 20 11 FF 00 06 20 11 FF 00 06 29 1F 06 51 19 06 29 1F 06 51 19 06 29 1F 06 51 19 06 29 1F 06 51 19 06 29 1F 06 51 19
					/*VESA optimize*/
					39 00 00 40 00 00 06 F0 55 AA 52 08 00
					39 00 00 40 00 00 02 E0 1C
					39 00 00 40 00 00 05 FF AA 55 A5 80
					39 00 00 40 00 00 02 6F 31
					39 00 00 00 00 00 03 F8 01 8E
					39 00 00 40 00 00 05 FF AA 55 A5 80
					39 00 00 40 00 00 02 6F 15
					39 00 00 40 00 00 03 F8 01 8D
					39 00 00 40 00 00 02 6F 16
					39 00 00 40 00 00 03 F4 02 74
					39 00 00 40 00 00 05 FF AA 55 A5 81
					39 00 00 40 00 00 02 6F 05
					39 00 00 40 00 00 03 FE 3C 3C
					39 00 00 40 00 00 02 6F 0D
					39 00 00 00 00 00 02 FB 80
					39 00 00 40 00 00 05 FF AA 55 A5 80
					39 00 00 40 00 00 02 6F 0A
					39 00 00 40 00 00 06 F6 70 70 70 70 70
					39 00 00 40 00 00 02 17 30
					//Source optimize
					39 00 00 40 00 00 05 FF AA 55 A5 80
					39 00 00 40 00 00 02 6F 2A
					39 00 00 40 00 00 02 F4 08
					//MIPI RX driving optimize
					39 00 00 40 00 00 05 FF AA 55 A5 82
					39 00 00 40 00 00 02 6F 09
					39 00 00 40 00 00 02 F2 FF
					39 00 00 40 00 00 06 F0 55 AA 52 08 01
					39 00 00 40 00 00 02 6F 06
					39 00 00 40 00 00 03 C5 0A 0A
					//close cmd2 cmd3
					39 00 00 40 00 00 06 F0 55 AA 52 00 00
					39 00 00 40 00 00 05 FF AA 55 A5 00
					39 00 00 40 00 00 05 2A 00 00 04 C7
					39 00 00 40 00 00 05 2B 00 00 0B 5F
					39 00 00 40 00 00 02 90 03
					39 00 00 40 00 00 02 6F 01
					39 00 00 40 00 00 02 90 43
					39 00 00 40 00 00 13 91 AB A8 00 20 C2 00 02 32 03 47 00 08 03 19 02 CE 10 F0
					39 00 00 40 00 00 02 6F 06
					39 00 00 40 00 00 02 6D 00
					/*24hz*/
					39 00 00 40 00 00 02 6D 05
					39 00 00 40 00 00 02 2F 30
					/*gir on*/
					39 00 00 40 00 00 02 5F 00
					39 00 00 40 00 00 02 35 00
					39 00 00 40 00 00 03 51 00 00
					39 00 00 40 00 00 02 53 20
					39 00 00 00 00 00 02 26 00
					39 00 00 00 00 00 02 5A 00
					39 00 00 40 00 00 02 6F 03
					39 00 00 40 00 00 03 35 00 04
					/* Display On */
					05 00 00 00 78 00 01 11
					05 00 00 00 00 00 01 29
				];
				qcom,mdss-dsi-on-command-state = "dsi_lp_mode";

				qcom,mdss-dsi-timing-switch-command = [
					/* Auto Dimming OFF */
					/*Frame skip OFF (Auto Mode)*/
					/*Frame Skip Mode 1*/
					39 00 00 40 00 00 06 F0 55 AA 52 08 00
					//AUTO OFF
					39 00 00 40 00 00 02 6F D9
					39 00 00 40 00 00 02 BA 04
					//OPT_fskip_abort_event OFF
					/*backlight off the back fun*/
					39 00 00 40 00 00 02 6F 08
					39 00 00 40 00 00 02 B2 80
					//close cmd2
					39 00 00 40 00 00 06 F0 55 AA 52 00 00
					/* Frequency Select 24Hz */
					39 00 00 40 00 00 02 6F 03
					39 00 00 40 00 00 03 35 00 04
					39 00 00 00 00 00 02 6D 05
				];

				qcom,mdss-dsi-timing-switch-command-state = "dsi_lp_mode";

				qcom,mdss-dsi-nolp-command = [
					39 00 00 00 00 00 03 51 00 00
					/* Aod Mode Off */
					39 00 00 40 00 00 02 38 00
					/*back to normal te*/
					39 00 00 40 00 00 02 6F 03
					39 00 00 00 00 00 03 35 00 04
				];
				qcom,mdss-dsi-nolp-command-update = <0x51 0 2>;
				qcom,mdss-dsi-nolp-command-state = "dsi_hs_mode";
			};
			timing@6 {
				#include "dsi-panel-n8-42-02-0a-prim-dsc-cmd-common.dtsi"
				cell-index = <6>;
				qcom,mdss-dsi-panel-framerate = <120>;
				/* ---------------------------- */
				/* | 15 - 14 | 13 - 7 | 6 - 0 | */
				/* ---------------------------- */
				/* |   mode  | sf fps | min fps| */
				/* ---------------------------- -*/
				/* mode: 1 idle, 2 auto, 3 qsync */
				/*   1 << 14 | 120 << 7 | 15      */
				qcom,mdss-dsi-h-sync-skew = <31759>;
				/* mode: 0 normal, 1 idle, 2 auto, 3 qsync, 4 diff, 5 test */
				mi,mdss-dsi-ddic-mode = "idle";
				mi,mdss-dsi-sf-framerate = <120>;
				mi,mdss-dsi-ddic-min-framerate = <15>;

				qcom,mdss-dsi-on-command = [
					/* Low frame switch skip 120 TE */
					39 00 00 40 00 00 06 F0 55 AA 52 08 03
					39 00 00 40 00 00 02 6F 0B
					39 00 00 00 00 00 02 C6 06
					/*IDLE 1*/
					39 00 00 40 00 00 06 F0 55 AA 52 08 00
					39 00 00 40 00 00 02 6F A4
					39 00 00 40 00 00 11 BA 03 03 03 06 01 01 01 06 00 01 01 14 00 00 01 16
					39 00 00 40 00 00 02 6F 1C
					39 00 00 40 00 00 11 BA 01 01 01 01 00 00 00 00 01 01 01 01 00 00 00 00
					39 00 00 40 00 00 02 6F 2C
					39 00 00 40 00 00 11 BA 01 01 01 01 01 01 01 01 01 01 01 01 00 00 00 00
					39 00 00 40 00 00 02 6F 3C
					39 00 00 40 00 00 11 BA 01 01 01 01 03 03 03 03 01 01 01 01 00 00 00 00
					39 00 00 40 00 00 02 6F 4C
					39 00 00 40 00 00 11 BA 01 01 01 01 0B 0B 04 0B 01 01 01 01 00 00 00 00
					/*thermal compensation DBI on*/
					39 00 00 40 00 00 06 F0 55 AA 52 08 08
					39 00 00 40 00 00 03 C2 22 80
					39 00 00 40 00 00 02 C7 13
					39 00 00 40 00 00 13 CB 00 00 00 00 00 00 00 00 00 00 00 00 00 00 00 00 00 00
					39 00 00 40 00 00 13 CC 00 00 00 00 00 00 00 00 00 00 00 00 00 00 00 00 00 00
					39 00 00 40 00 00 13 CE 00 00 00 00 00 00 00 00 00 00 00 00 00 00 00 00 00 00
					39 00 00 40 00 00 03 D3 80 01
					39 00 00 40 00 00 02 6F 02
					39 00 00 40 00 00 06 D3 10 00 98 00 6B
					39 00 00 00 00 00 05 67 80 40 80 80
					/*on ddic corner*/
					39 00 00 40 00 00 06 F0 55 AA 52 08 07
					39 00 00 40 00 00 02 6F 03
					39 00 00 40 00 00 05 C0 00 00 00 00
					39 00 00 40 00 00 16 C1 30 0F 02 71 09 61 F6 6E 3F FD BA F2 3F F9 AE 9E 00 00 89 54 40
					39 00 00 40 00 00 02 6F 15
					39 00 00 40 00 00 11 C1 0F 00 37 AF 00 00 19 37 F0 E7 89 0B 9F 30 FF 00
					39 00 00 40 00 00 02 6F 25
					39 00 00 40 00 00 08 C1 00 2F 37 00 10 18 00
					39 00 00 40 00 00 16 C2 30 0F 27 10 00 64 F8 30 3F FA AA 38 3F FF 84 90 00 00 27 10 00
					39 00 00 40 00 00 02 6F 15
					39 00 00 40 00 00 11 C2 03 00 00 0A 00 56 F6 B3 F0 62 F6 06 2C C0 00 FE
					39 00 00 40 00 00 02 6F 25
					39 00 00 40 00 00 08 C2 00 01 09 00 4F 56 00
					39 00 00 00 00 00 16 C3 30 0F 01 69 01 21 FD 7A 3F FE 6A 5A 3F FE C1 F2 00 00 3C C7 39
					39 00 00 40 00 00 02 6F 15
					39 00 00 40 00 00 11 C3 0C 00 0A 36 00 19 55 44 F0 C5 D5 09 E9 F0 FF FF
					39 00 00 40 00 00 02 6F 25
					39 00 00 40 00 00 08 C3 44 91 99 00 10 18 00
					39 00 00 40 00 00 16 C4 3C 00 2F 44 00 64 08 98 3F F5 0A 60 00 00 00 00 00 00 00 00 00
					39 00 00 40 00 00 02 6F 15
					39 00 00 40 00 00 11 C4 99 00 00 0A AB 69 09 B3 C0 62 0A 00 00 00 00 00
					39 00 00 40 00 00 02 6F 25
					39 00 00 40 00 00 08 C4 44 BF C7 00 4F 57 00
					39 00 00 40 00 00 16 C5 3C 00 01 69 01 21 02 86 3F FD D5 78 00 00 B8 D8 00 00 02 2B F1
					39 00 00 40 00 00 02 6F 15
					39 00 00 40 00 00 11 C5 2E 00 0A 36 BB 0A 46 44 C0 C5 2B 00 00 30 FF 00
					39 00 00 40 00 00 02 6F 25
					39 00 00 40 00 00 08 C5 00 2F 37 BB 47 4F 00
					39 00 00 00 00 00 16 C6 3C 00 02 71 0B 64 0A 8C 3F FC 9A DC 00 04 C0 CC 00 00 03 67 95
					39 00 00 40 00 00 02 6F 15
					39 00 00 40 00 00 11 C6 09 00 37 B4 BB 46 5F 37 C0 E7 7C 00 00 30 FF 00
					39 00 00 40 00 00 02 6F 25
					39 00 00 00 00 00 08 C6 00 01 09 BB 07 0F 00
					39 00 00 40 00 00 16 C7 31 00 06 E4 06 E4 00 00 3F FD BD 30 3F FD BD 30 00 00 34 0E 78
					39 00 00 40 00 00 02 6F 15
					39 00 00 40 00 00 11 C7 0C 22 38 63 00 23 4E 44 F0 D6 D6 06 E4 F0 FF FF
					39 00 00 40 00 00 02 6F 25
					39 00 00 40 00 00 08 C7 44 91 99 BB 47 4F 00
					39 00 00 40 00 00 16 C8 3D 00 06 E4 06 E4 00 00 3F FD BD 30 00 00 00 00 00 00 02 49 B4
					39 00 00 40 00 00 02 6F 15
					39 00 00 00 00 00 11 C8 1D 22 38 63 00 4F 7A 44 C0 D6 2A 00 00 30 FF 00
					39 00 00 40 00 00 02 6F 25
					39 00 00 40 00 00 08 C8 44 BF C7 BB 07 0F 00
					39 00 00 40 00 00 0F D1 80 00 00 00 00 04 C7 80 00 01 94 B0 04 C7
					39 00 00 40 00 00 02 6F 0E
					39 00 00 40 00 00 0F D1 80 00 01 AB B1 04 C7 FF FF A4 DE 50 04 C7
					39 00 00 40 00 00 02 6F 1C
					39 00 00 40 00 00 0F D1 FF FF AD 0A 89 04 C7 FF FE ED A5 A0 04 C7
					39 00 00 40 00 00 02 6F 2A
					39 00 00 40 00 00 0C D1 80 00 02 49 B4 04 C7 FF FF D0 84
					39 00 00 00 00 00 12 D2 F0 04 C7 00 00 00 00 00 00 00 00 00 00 00 00 00 00
					/*backlight*/
					39 00 00 40 00 00 06 F0 55 AA 52 08 00
					39 00 00 40 00 00 02 6F 08
					//OPT_fskip_abort_event on
					39 00 00 40 00 00 02 B2 C0
					//ESD DECTED
					39 00 00 40 00 00 06 F0 55 AA 52 08 00
					39 00 00 40 00 00 03 BE 47 45
					//normal low,active high
					39 00 00 40 00 00 02 6F 05
					39 00 00 40 00 00 02 BE 28
					39 00 00 40 00 00 02 6F 19
					39 00 00 40 00 00 05 BE 10 91 00 AB
					//VESA_PPS_DT_BLOCK_SLO_DISPON=1
					39 00 00 40 00 00 02 6F 0D
					39 00 00 40 00 00 02 D8 42
					//AUTO ENABLE
					39 00 00 40 00 00 06 F0 55 AA 52 08 00
					39 00 00 40 00 00 02 6F D9
					39 00 00 40 00 00 02 BA 00
					//DVDD enhance
					39 00 00 40 00 00 06 F0 55 AA 52 08 01
					39 00 00 40 00 00 02 6F 05
					39 00 00 40 00 00 04 C5 00 00 00
					//EM pulse multi to one optimize
					39 00 00 40 00 00 02 E5 00
					//VINITN2 bias adjust
					39 00 00 40 00 00 05 FF AA 55 A5 80
					39 00 00 40 00 00 02 6F 32
					39 00 00 40 00 00 02 F9 00
					//AOD WB timing optimize
					39 00 00 40 00 00 05 FF AA 55 A5 81
					39 00 00 40 00 00 02 6F 02
					39 00 00 40 00 00 02 F9 84
					//AOD SOP optimize
					39 00 00 40 00 00 05 FF AA 55 A5 81
					39 00 00 40 00 00 02 6F 13
					39 00 00 40 00 00 02 F9 00
					//Enalbe fskip_extend vfp function
					39 00 00 40 00 00 05 FF AA 55 A5 81
					39 00 00 40 00 00 02 6F 0C
					39 00 00 40 00 00 02 FD 08
					//Frameskip Chopper timing adjust
					39 00 00 40 00 00 05 FF AA 55 A5 81
					39 00 00 40 00 00 02 6F 10
					39 00 00 40 00 00 02 FB 40
					//Disable VOLTP output for power saving
					39 00 00 40 00 00 05 FF AA 55 A5 80
					39 00 00 40 00 00 02 6F 42
					39 00 00 40 00 00 02 F4 00
					39 00 00 40 00 00 02 6F 49
					39 00 00 00 00 00 02 F2 10
					/*video trim*/
					39 00 00 40 00 00 06 F0 55 AA 52 08 01
					39 00 00 40 00 00 2A C3 DD 06 20 11 FF 00 06 20 11 FF 00 06 29 1F 06 51 19 06 29 1F 06 51 19 06 29 1F 06 51 19 06 29 1F 06 51 19 06 29 1F 06 51 19
					/*VESA optimize*/
					39 00 00 40 00 00 06 F0 55 AA 52 08 00
					39 00 00 40 00 00 02 E0 1C
					39 00 00 40 00 00 05 FF AA 55 A5 80
					39 00 00 40 00 00 02 6F 31
					39 00 00 00 00 00 03 F8 01 8E
					39 00 00 40 00 00 05 FF AA 55 A5 80
					39 00 00 40 00 00 02 6F 15
					39 00 00 40 00 00 03 F8 01 8D
					39 00 00 40 00 00 02 6F 16
					39 00 00 40 00 00 03 F4 02 74
					39 00 00 40 00 00 05 FF AA 55 A5 81
					39 00 00 40 00 00 02 6F 05
					39 00 00 40 00 00 03 FE 3C 3C
					39 00 00 40 00 00 02 6F 0D
					39 00 00 00 00 00 02 FB 80
					39 00 00 40 00 00 05 FF AA 55 A5 80
					39 00 00 40 00 00 02 6F 0A
					39 00 00 40 00 00 06 F6 70 70 70 70 70
					39 00 00 40 00 00 02 17 30
					//Source optimize
					39 00 00 40 00 00 05 FF AA 55 A5 80
					39 00 00 40 00 00 02 6F 2A
					39 00 00 40 00 00 02 F4 08
					//MIPI RX driving optimize
					39 00 00 40 00 00 05 FF AA 55 A5 82
					39 00 00 40 00 00 02 6F 09
					39 00 00 40 00 00 02 F2 FF
					39 00 00 40 00 00 06 F0 55 AA 52 08 01
					39 00 00 40 00 00 02 6F 06
					39 00 00 40 00 00 03 C5 0A 0A
					//close cmd2 cmd3
					39 00 00 40 00 00 06 F0 55 AA 52 00 00
					39 00 00 40 00 00 05 FF AA 55 A5 00
					39 00 00 40 00 00 05 2A 00 00 04 C7
					39 00 00 40 00 00 05 2B 00 00 0B 5F
					39 00 00 40 00 00 02 90 03
					39 00 00 40 00 00 02 6F 01
					39 00 00 40 00 00 02 90 43
					39 00 00 40 00 00 13 91 AB A8 00 20 C2 00 02 32 03 47 00 08 03 19 02 CE 10 F0
					39 00 00 40 00 00 02 6F 06
					39 00 00 40 00 00 02 6D 00
					/*15hz*/
					39 00 00 40 00 00 02 6D 07
					39 00 00 40 00 00 02 2F 30
					/*gir on*/
					39 00 00 40 00 00 02 5F 00
					39 00 00 40 00 00 02 35 00
					39 00 00 40 00 00 03 51 00 00
					39 00 00 40 00 00 02 53 20
					39 00 00 00 00 00 02 26 00
					39 00 00 00 00 00 02 5A 00
					/* Display On */
					05 00 00 00 78 00 01 11
					05 00 00 00 00 00 01 29
				];
				qcom,mdss-dsi-on-command-state = "dsi_lp_mode";

				qcom,mdss-dsi-timing-switch-command = [
					/* Auto Dimming OFF */
					/*Frame skip OFF (Auto Mode)*/
					/*Frame Skip Mode 1*/
					39 00 00 40 00 00 06 F0 55 AA 52 08 00
					//AUTO ENABLE
					39 00 00 40 00 00 02 6F D9
					39 00 00 40 00 00 02 BA 00
					//OPT_fskip_abort_event ON
					/*backlight enable the back fun*/
					39 00 00 40 00 00 02 6F 08
					39 00 00 40 00 00 02 B2 C0
					//close cmd2
					39 00 00 40 00 00 06 F0 55 AA 52 00 00
					/* Frequency Select 15Hz */
					39 00 00 40 00 00 02 6F 03
					39 00 00 40 00 00 03 35 00 00
					39 00 00 00 00 00 02 6D 07
				];

				qcom,mdss-dsi-timing-switch-command-state = "dsi_lp_mode";

				qcom,mdss-dsi-nolp-command = [
					39 00 00 00 00 00 03 51 00 00
					/* Aod Mode Off */
					39 00 00 40 00 00 02 38 00
					/*back to normal te*/
					39 00 00 40 00 00 02 6F 03
					39 00 00 00 00 00 03 35 00 00
				];
				qcom,mdss-dsi-nolp-command-update = <0x51 0 2>;
				qcom,mdss-dsi-nolp-command-state = "dsi_hs_mode";
			};
			timing@7 {
				#include "dsi-panel-n8-42-02-0a-prim-dsc-cmd-common.dtsi"
				cell-index = <7>;
				qcom,mdss-dsi-panel-framerate = <120>;
				/* ---------------------------- */
				/* | 15 - 14 | 13 - 7 | 6 - 0 | */
				/* ---------------------------- */
				/* |   mode  | sf fps | min fps| */
				/* ---------------------------- -*/
				/* mode: 1 idle, 2 auto, 3 qsync */
				/*   1 << 14 | 120 << 7 | 10      */
				qcom,mdss-dsi-h-sync-skew = <31754>;
				/* mode: 0 normal, 1 idle, 2 auto, 3 qsync, 4 diff, 5 test */
				mi,mdss-dsi-ddic-mode = "idle";
				mi,mdss-dsi-sf-framerate = <120>;
				mi,mdss-dsi-ddic-min-framerate = <10>;

				qcom,mdss-dsi-on-command = [
					/* Low frame switch skip 120 TE */
					39 00 00 40 00 00 06 F0 55 AA 52 08 03
					39 00 00 40 00 00 02 6F 0B
					39 00 00 00 00 00 02 C6 06
					/*IDLE 1*/
					39 00 00 40 00 00 06 F0 55 AA 52 08 00
					39 00 00 40 00 00 02 6F A4
					39 00 00 40 00 00 11 BA 03 03 03 06 01 01 01 06 00 01 01 14 00 00 01 16
					39 00 00 40 00 00 02 6F 1C
					39 00 00 40 00 00 11 BA 01 01 01 01 00 00 00 00 01 01 01 01 00 00 00 00
					39 00 00 40 00 00 02 6F 2C
					39 00 00 40 00 00 11 BA 01 01 01 01 01 01 01 01 01 01 01 01 00 00 00 00
					39 00 00 40 00 00 02 6F 3C
					39 00 00 40 00 00 11 BA 01 01 01 01 03 03 03 03 01 01 01 01 00 00 00 00
					39 00 00 40 00 00 02 6F 4C
					39 00 00 40 00 00 11 BA 01 01 01 01 0B 0B 04 0B 01 01 01 01 00 00 00 00
					/*thermal compensation DBI on*/
					39 00 00 40 00 00 06 F0 55 AA 52 08 08
					39 00 00 40 00 00 03 C2 22 80
					39 00 00 40 00 00 02 C7 13
					39 00 00 40 00 00 13 CB 00 00 00 00 00 00 00 00 00 00 00 00 00 00 00 00 00 00
					39 00 00 40 00 00 13 CC 00 00 00 00 00 00 00 00 00 00 00 00 00 00 00 00 00 00
					39 00 00 40 00 00 13 CE 00 00 00 00 00 00 00 00 00 00 00 00 00 00 00 00 00 00
					39 00 00 40 00 00 03 D3 80 01
					39 00 00 40 00 00 02 6F 02
					39 00 00 40 00 00 06 D3 10 00 98 00 6B
					39 00 00 00 00 00 05 67 80 40 80 80
					/*on ddic corner*/
					39 00 00 40 00 00 06 F0 55 AA 52 08 07
					39 00 00 40 00 00 02 6F 03
					39 00 00 40 00 00 05 C0 00 00 00 00
					39 00 00 40 00 00 16 C1 30 0F 02 71 09 61 F6 6E 3F FD BA F2 3F F9 AE 9E 00 00 89 54 40
					39 00 00 40 00 00 02 6F 15
					39 00 00 40 00 00 11 C1 0F 00 37 AF 00 00 19 37 F0 E7 89 0B 9F 30 FF 00
					39 00 00 40 00 00 02 6F 25
					39 00 00 40 00 00 08 C1 00 2F 37 00 10 18 00
					39 00 00 40 00 00 16 C2 30 0F 27 10 00 64 F8 30 3F FA AA 38 3F FF 84 90 00 00 27 10 00
					39 00 00 40 00 00 02 6F 15
					39 00 00 40 00 00 11 C2 03 00 00 0A 00 56 F6 B3 F0 62 F6 06 2C C0 00 FE
					39 00 00 40 00 00 02 6F 25
					39 00 00 40 00 00 08 C2 00 01 09 00 4F 56 00
					39 00 00 00 00 00 16 C3 30 0F 01 69 01 21 FD 7A 3F FE 6A 5A 3F FE C1 F2 00 00 3C C7 39
					39 00 00 40 00 00 02 6F 15
					39 00 00 40 00 00 11 C3 0C 00 0A 36 00 19 55 44 F0 C5 D5 09 E9 F0 FF FF
					39 00 00 40 00 00 02 6F 25
					39 00 00 40 00 00 08 C3 44 91 99 00 10 18 00
					39 00 00 40 00 00 16 C4 3C 00 2F 44 00 64 08 98 3F F5 0A 60 00 00 00 00 00 00 00 00 00
					39 00 00 40 00 00 02 6F 15
					39 00 00 40 00 00 11 C4 99 00 00 0A AB 69 09 B3 C0 62 0A 00 00 00 00 00
					39 00 00 40 00 00 02 6F 25
					39 00 00 40 00 00 08 C4 44 BF C7 00 4F 57 00
					39 00 00 40 00 00 16 C5 3C 00 01 69 01 21 02 86 3F FD D5 78 00 00 B8 D8 00 00 02 2B F1
					39 00 00 40 00 00 02 6F 15
					39 00 00 40 00 00 11 C5 2E 00 0A 36 BB 0A 46 44 C0 C5 2B 00 00 30 FF 00
					39 00 00 40 00 00 02 6F 25
					39 00 00 40 00 00 08 C5 00 2F 37 BB 47 4F 00
					39 00 00 00 00 00 16 C6 3C 00 02 71 0B 64 0A 8C 3F FC 9A DC 00 04 C0 CC 00 00 03 67 95
					39 00 00 40 00 00 02 6F 15
					39 00 00 40 00 00 11 C6 09 00 37 B4 BB 46 5F 37 C0 E7 7C 00 00 30 FF 00
					39 00 00 40 00 00 02 6F 25
					39 00 00 00 00 00 08 C6 00 01 09 BB 07 0F 00
					39 00 00 40 00 00 16 C7 31 00 06 E4 06 E4 00 00 3F FD BD 30 3F FD BD 30 00 00 34 0E 78
					39 00 00 40 00 00 02 6F 15
					39 00 00 40 00 00 11 C7 0C 22 38 63 00 23 4E 44 F0 D6 D6 06 E4 F0 FF FF
					39 00 00 40 00 00 02 6F 25
					39 00 00 40 00 00 08 C7 44 91 99 BB 47 4F 00
					39 00 00 40 00 00 16 C8 3D 00 06 E4 06 E4 00 00 3F FD BD 30 00 00 00 00 00 00 02 49 B4
					39 00 00 40 00 00 02 6F 15
					39 00 00 00 00 00 11 C8 1D 22 38 63 00 4F 7A 44 C0 D6 2A 00 00 30 FF 00
					39 00 00 40 00 00 02 6F 25
					39 00 00 40 00 00 08 C8 44 BF C7 BB 07 0F 00
					39 00 00 40 00 00 0F D1 80 00 00 00 00 04 C7 80 00 01 94 B0 04 C7
					39 00 00 40 00 00 02 6F 0E
					39 00 00 40 00 00 0F D1 80 00 01 AB B1 04 C7 FF FF A4 DE 50 04 C7
					39 00 00 40 00 00 02 6F 1C
					39 00 00 40 00 00 0F D1 FF FF AD 0A 89 04 C7 FF FE ED A5 A0 04 C7
					39 00 00 40 00 00 02 6F 2A
					39 00 00 40 00 00 0C D1 80 00 02 49 B4 04 C7 FF FF D0 84
					39 00 00 00 00 00 12 D2 F0 04 C7 00 00 00 00 00 00 00 00 00 00 00 00 00 00
					/*backlight*/
					39 00 00 40 00 00 06 F0 55 AA 52 08 00
					39 00 00 40 00 00 02 6F 08
					//OPT_fskip_abort_event on
					39 00 00 40 00 00 02 B2 C0
					//ESD DECTED
					39 00 00 40 00 00 06 F0 55 AA 52 08 00
					39 00 00 40 00 00 03 BE 47 45
					//normal low,active high
					39 00 00 40 00 00 02 6F 05
					39 00 00 40 00 00 02 BE 28
					39 00 00 40 00 00 02 6F 19
					39 00 00 40 00 00 05 BE 10 91 00 AB
					//VESA_PPS_DT_BLOCK_SLO_DISPON=1
					39 00 00 40 00 00 02 6F 0D
					39 00 00 40 00 00 02 D8 42
					//AUTO ENABLE
					39 00 00 40 00 00 06 F0 55 AA 52 08 00
					39 00 00 40 00 00 02 6F D9
					39 00 00 40 00 00 02 BA 00
					//DVDD enhance
					39 00 00 40 00 00 06 F0 55 AA 52 08 01
					39 00 00 40 00 00 02 6F 05
					39 00 00 40 00 00 04 C5 00 00 00
					//EM pulse multi to one optimize
					39 00 00 40 00 00 02 E5 00
					//VINITN2 bias adjust
					39 00 00 40 00 00 05 FF AA 55 A5 80
					39 00 00 40 00 00 02 6F 32
					39 00 00 40 00 00 02 F9 00
					//AOD WB timing optimize
					39 00 00 40 00 00 05 FF AA 55 A5 81
					39 00 00 40 00 00 02 6F 02
					39 00 00 40 00 00 02 F9 84
					//AOD SOP optimize
					39 00 00 40 00 00 05 FF AA 55 A5 81
					39 00 00 40 00 00 02 6F 13
					39 00 00 40 00 00 02 F9 00
					//Enalbe fskip_extend vfp function
					39 00 00 40 00 00 05 FF AA 55 A5 81
					39 00 00 40 00 00 02 6F 0C
					39 00 00 40 00 00 02 FD 08
					//Frameskip Chopper timing adjust
					39 00 00 40 00 00 05 FF AA 55 A5 81
					39 00 00 40 00 00 02 6F 10
					39 00 00 40 00 00 02 FB 40
					//Disable VOLTP output for power saving
					39 00 00 40 00 00 05 FF AA 55 A5 80
					39 00 00 40 00 00 02 6F 42
					39 00 00 40 00 00 02 F4 00
					39 00 00 40 00 00 02 6F 49
					39 00 00 00 00 00 02 F2 10
					/*video trim*/
					39 00 00 40 00 00 06 F0 55 AA 52 08 01
					39 00 00 40 00 00 2A C3 DD 06 20 11 FF 00 06 20 11 FF 00 06 29 1F 06 51 19 06 29 1F 06 51 19 06 29 1F 06 51 19 06 29 1F 06 51 19 06 29 1F 06 51 19
					/*VESA optimize*/
					39 00 00 40 00 00 06 F0 55 AA 52 08 00
					39 00 00 40 00 00 02 E0 1C
					39 00 00 40 00 00 05 FF AA 55 A5 80
					39 00 00 40 00 00 02 6F 31
					39 00 00 00 00 00 03 F8 01 8E
					39 00 00 40 00 00 05 FF AA 55 A5 80
					39 00 00 40 00 00 02 6F 15
					39 00 00 40 00 00 03 F8 01 8D
					39 00 00 40 00 00 02 6F 16
					39 00 00 40 00 00 03 F4 02 74
					39 00 00 40 00 00 05 FF AA 55 A5 81
					39 00 00 40 00 00 02 6F 05
					39 00 00 40 00 00 03 FE 3C 3C
					39 00 00 40 00 00 02 6F 0D
					39 00 00 00 00 00 02 FB 80
					39 00 00 40 00 00 05 FF AA 55 A5 80
					39 00 00 40 00 00 02 6F 0A
					39 00 00 40 00 00 06 F6 70 70 70 70 70
					39 00 00 40 00 00 02 17 30
					//Source optimize
					39 00 00 40 00 00 05 FF AA 55 A5 80
					39 00 00 40 00 00 02 6F 2A
					39 00 00 40 00 00 02 F4 08
					//MIPI RX driving optimize
					39 00 00 40 00 00 05 FF AA 55 A5 82
					39 00 00 40 00 00 02 6F 09
					39 00 00 40 00 00 02 F2 FF
					39 00 00 40 00 00 06 F0 55 AA 52 08 01
					39 00 00 40 00 00 02 6F 06
					39 00 00 40 00 00 03 C5 0A 0A
					//close cmd2 cmd3
					39 00 00 40 00 00 06 F0 55 AA 52 00 00
					39 00 00 40 00 00 05 FF AA 55 A5 00
					39 00 00 40 00 00 05 2A 00 00 04 C7
					39 00 00 40 00 00 05 2B 00 00 0B 5F
					39 00 00 40 00 00 02 90 03
					39 00 00 40 00 00 02 6F 01
					39 00 00 40 00 00 02 90 43
					39 00 00 40 00 00 13 91 AB A8 00 20 C2 00 02 32 03 47 00 08 03 19 02 CE 10 F0
					39 00 00 40 00 00 02 6F 06
					39 00 00 40 00 00 02 6D 00
					/*10hz*/
					39 00 00 40 00 00 02 6D 08
					39 00 00 40 00 00 02 2F 30
					/*gir on*/
					39 00 00 40 00 00 02 5F 00
					39 00 00 40 00 00 02 35 00
					39 00 00 40 00 00 03 51 00 00
					39 00 00 40 00 00 02 53 20
					39 00 00 00 00 00 02 26 00
					39 00 00 00 00 00 02 5A 00
					/* Display On */
					05 00 00 00 78 00 01 11
					05 00 00 00 00 00 01 29
				];
				qcom,mdss-dsi-on-command-state = "dsi_lp_mode";

				qcom,mdss-dsi-timing-switch-command = [
					/* Auto Dimming OFF */
					/*Frame skip OFF (Auto Mode)*/
					/*Frame Skip Mode 1*/
					39 00 00 40 00 00 06 F0 55 AA 52 08 00
					//AUTO ENABLE
					39 00 00 40 00 00 02 6F D9
					39 00 00 40 00 00 02 BA 00
					//OPT_fskip_abort_event ON
					/*backlight enable the back fun*/
					39 00 00 40 00 00 02 6F 08
					39 00 00 40 00 00 02 B2 C0
					//close cmd2
					39 00 00 40 00 00 06 F0 55 AA 52 00 00
					/* Frequency Select 10Hz */
					39 00 00 40 00 00 02 6F 03
					39 00 00 40 00 00 03 35 00 00
					39 00 00 00 00 00 02 6D 08
				];

				qcom,mdss-dsi-timing-switch-command-state = "dsi_lp_mode";

				qcom,mdss-dsi-nolp-command = [
					39 00 00 00 00 00 03 51 00 00
					/* Aod Mode Off */
					39 00 00 40 00 00 02 38 00
					/*back to normal te*/
					39 00 00 40 00 00 02 6F 03
					39 00 00 00 00 00 03 35 00 00
				];
				qcom,mdss-dsi-nolp-command-update = <0x51 0 2>;
				qcom,mdss-dsi-nolp-command-state = "dsi_hs_mode";
			};
			timing@8 {
				#include "dsi-panel-n8-42-02-0a-prim-dsc-cmd-common.dtsi"
				cell-index = <8>;
				qcom,mdss-dsi-panel-framerate = <120>;
				/* ---------------------------- */
				/* | 15 - 14 | 13 - 7 | 6 - 0 | */
				/* ---------------------------- */
				/* |   mode  | sf fps | min fps| */
				/* ---------------------------- -*/
				/* mode: 1 idle, 2 auto, 3 qsync */
				/*   1 << 14 | 120 << 7 | 1      */
				qcom,mdss-dsi-h-sync-skew = <31745>;
				/* mode: 0 normal, 1 idle, 2 auto, 3 qsync, 4 diff, 5 test */
				mi,mdss-dsi-ddic-mode = "idle";
				mi,mdss-dsi-sf-framerate = <120>;
				mi,mdss-dsi-ddic-min-framerate = <1>;

				qcom,mdss-dsi-on-command = [
					/* Low frame switch skip 120 TE */
					39 00 00 40 00 00 06 F0 55 AA 52 08 03
					39 00 00 40 00 00 02 6F 0B
					39 00 00 00 00 00 02 C6 06
					/*IDLE 1*/
					39 00 00 40 00 00 06 F0 55 AA 52 08 00
					39 00 00 40 00 00 02 6F A4
					39 00 00 40 00 00 11 BA 03 03 03 06 01 01 01 06 00 01 01 14 00 00 01 16
					39 00 00 40 00 00 02 6F 1C
					39 00 00 40 00 00 11 BA 01 01 01 01 00 00 00 00 01 01 01 01 00 00 00 00
					39 00 00 40 00 00 02 6F 2C
					39 00 00 40 00 00 11 BA 01 01 01 01 01 01 01 01 01 01 01 01 00 00 00 00
					39 00 00 40 00 00 02 6F 3C
					39 00 00 40 00 00 11 BA 01 01 01 01 03 03 03 03 01 01 01 01 00 00 00 00
					39 00 00 40 00 00 02 6F 4C
					39 00 00 40 00 00 11 BA 01 01 01 01 0B 0B 04 0B 01 01 01 01 00 00 00 00
					/*thermal compensation DBI on*/
					39 00 00 40 00 00 06 F0 55 AA 52 08 08
					39 00 00 40 00 00 03 C2 22 80
					39 00 00 40 00 00 02 C7 13
					39 00 00 40 00 00 13 CB 00 00 00 00 00 00 00 00 00 00 00 00 00 00 00 00 00 00
					39 00 00 40 00 00 13 CC 00 00 00 00 00 00 00 00 00 00 00 00 00 00 00 00 00 00
					39 00 00 40 00 00 13 CE 00 00 00 00 00 00 00 00 00 00 00 00 00 00 00 00 00 00
					39 00 00 40 00 00 03 D3 80 01
					39 00 00 40 00 00 02 6F 02
					39 00 00 40 00 00 06 D3 10 00 98 00 6B
					39 00 00 00 00 00 05 67 80 40 80 80
					/*on ddic corner*/
					39 00 00 40 00 00 06 F0 55 AA 52 08 07
					39 00 00 40 00 00 02 6F 03
					39 00 00 40 00 00 05 C0 00 00 00 00
					39 00 00 40 00 00 16 C1 30 0F 02 71 09 61 F6 6E 3F FD BA F2 3F F9 AE 9E 00 00 89 54 40
					39 00 00 40 00 00 02 6F 15
					39 00 00 40 00 00 11 C1 0F 00 37 AF 00 00 19 37 F0 E7 89 0B 9F 30 FF 00
					39 00 00 40 00 00 02 6F 25
					39 00 00 40 00 00 08 C1 00 2F 37 00 10 18 00
					39 00 00 40 00 00 16 C2 30 0F 27 10 00 64 F8 30 3F FA AA 38 3F FF 84 90 00 00 27 10 00
					39 00 00 40 00 00 02 6F 15
					39 00 00 40 00 00 11 C2 03 00 00 0A 00 56 F6 B3 F0 62 F6 06 2C C0 00 FE
					39 00 00 40 00 00 02 6F 25
					39 00 00 40 00 00 08 C2 00 01 09 00 4F 56 00
					39 00 00 00 00 00 16 C3 30 0F 01 69 01 21 FD 7A 3F FE 6A 5A 3F FE C1 F2 00 00 3C C7 39
					39 00 00 40 00 00 02 6F 15
					39 00 00 40 00 00 11 C3 0C 00 0A 36 00 19 55 44 F0 C5 D5 09 E9 F0 FF FF
					39 00 00 40 00 00 02 6F 25
					39 00 00 40 00 00 08 C3 44 91 99 00 10 18 00
					39 00 00 40 00 00 16 C4 3C 00 2F 44 00 64 08 98 3F F5 0A 60 00 00 00 00 00 00 00 00 00
					39 00 00 40 00 00 02 6F 15
					39 00 00 40 00 00 11 C4 99 00 00 0A AB 69 09 B3 C0 62 0A 00 00 00 00 00
					39 00 00 40 00 00 02 6F 25
					39 00 00 40 00 00 08 C4 44 BF C7 00 4F 57 00
					39 00 00 40 00 00 16 C5 3C 00 01 69 01 21 02 86 3F FD D5 78 00 00 B8 D8 00 00 02 2B F1
					39 00 00 40 00 00 02 6F 15
					39 00 00 40 00 00 11 C5 2E 00 0A 36 BB 0A 46 44 C0 C5 2B 00 00 30 FF 00
					39 00 00 40 00 00 02 6F 25
					39 00 00 40 00 00 08 C5 00 2F 37 BB 47 4F 00
					39 00 00 00 00 00 16 C6 3C 00 02 71 0B 64 0A 8C 3F FC 9A DC 00 04 C0 CC 00 00 03 67 95
					39 00 00 40 00 00 02 6F 15
					39 00 00 40 00 00 11 C6 09 00 37 B4 BB 46 5F 37 C0 E7 7C 00 00 30 FF 00
					39 00 00 40 00 00 02 6F 25
					39 00 00 00 00 00 08 C6 00 01 09 BB 07 0F 00
					39 00 00 40 00 00 16 C7 31 00 06 E4 06 E4 00 00 3F FD BD 30 3F FD BD 30 00 00 34 0E 78
					39 00 00 40 00 00 02 6F 15
					39 00 00 40 00 00 11 C7 0C 22 38 63 00 23 4E 44 F0 D6 D6 06 E4 F0 FF FF
					39 00 00 40 00 00 02 6F 25
					39 00 00 40 00 00 08 C7 44 91 99 BB 47 4F 00
					39 00 00 40 00 00 16 C8 3D 00 06 E4 06 E4 00 00 3F FD BD 30 00 00 00 00 00 00 02 49 B4
					39 00 00 40 00 00 02 6F 15
					39 00 00 00 00 00 11 C8 1D 22 38 63 00 4F 7A 44 C0 D6 2A 00 00 30 FF 00
					39 00 00 40 00 00 02 6F 25
					39 00 00 40 00 00 08 C8 44 BF C7 BB 07 0F 00
					39 00 00 40 00 00 0F D1 80 00 00 00 00 04 C7 80 00 01 94 B0 04 C7
					39 00 00 40 00 00 02 6F 0E
					39 00 00 40 00 00 0F D1 80 00 01 AB B1 04 C7 FF FF A4 DE 50 04 C7
					39 00 00 40 00 00 02 6F 1C
					39 00 00 40 00 00 0F D1 FF FF AD 0A 89 04 C7 FF FE ED A5 A0 04 C7
					39 00 00 40 00 00 02 6F 2A
					39 00 00 40 00 00 0C D1 80 00 02 49 B4 04 C7 FF FF D0 84
					39 00 00 00 00 00 12 D2 F0 04 C7 00 00 00 00 00 00 00 00 00 00 00 00 00 00
					/*backlight*/
					39 00 00 40 00 00 06 F0 55 AA 52 08 00
					39 00 00 40 00 00 02 6F 08
					//OPT_fskip_abort_event on
					39 00 00 40 00 00 02 B2 C0
					//ESD DECTED
					39 00 00 40 00 00 06 F0 55 AA 52 08 00
					39 00 00 40 00 00 03 BE 47 45
					//normal low,active high
					39 00 00 40 00 00 02 6F 05
					39 00 00 40 00 00 02 BE 28
					39 00 00 40 00 00 02 6F 19
					39 00 00 40 00 00 05 BE 10 91 00 AB
					//VESA_PPS_DT_BLOCK_SLO_DISPON=1
					39 00 00 40 00 00 02 6F 0D
					39 00 00 40 00 00 02 D8 42
					//AUTO ENABLE
					39 00 00 40 00 00 06 F0 55 AA 52 08 00
					39 00 00 40 00 00 02 6F D9
					39 00 00 40 00 00 02 BA 00
					//DVDD enhance
					39 00 00 40 00 00 06 F0 55 AA 52 08 01
					39 00 00 40 00 00 02 6F 05
					39 00 00 40 00 00 04 C5 00 00 00
					//EM pulse multi to one optimize
					39 00 00 40 00 00 02 E5 00
					//VINITN2 bias adjust
					39 00 00 40 00 00 05 FF AA 55 A5 80
					39 00 00 40 00 00 02 6F 32
					39 00 00 40 00 00 02 F9 00
					//AOD WB timing optimize
					39 00 00 40 00 00 05 FF AA 55 A5 81
					39 00 00 40 00 00 02 6F 02
					39 00 00 40 00 00 02 F9 84
					//AOD SOP optimize
					39 00 00 40 00 00 05 FF AA 55 A5 81
					39 00 00 40 00 00 02 6F 13
					39 00 00 40 00 00 02 F9 00
					//Enalbe fskip_extend vfp function
					39 00 00 40 00 00 05 FF AA 55 A5 81
					39 00 00 40 00 00 02 6F 0C
					39 00 00 40 00 00 02 FD 08
					//Frameskip Chopper timing adjust
					39 00 00 40 00 00 05 FF AA 55 A5 81
					39 00 00 40 00 00 02 6F 10
					39 00 00 40 00 00 02 FB 40
					//Disable VOLTP output for power saving
					39 00 00 40 00 00 05 FF AA 55 A5 80
					39 00 00 40 00 00 02 6F 42
					39 00 00 40 00 00 02 F4 00
					39 00 00 40 00 00 02 6F 49
					39 00 00 00 00 00 02 F2 10
					/*video trim*/
					39 00 00 40 00 00 06 F0 55 AA 52 08 01
					39 00 00 40 00 00 2A C3 DD 06 20 11 FF 00 06 20 11 FF 00 06 29 1F 06 51 19 06 29 1F 06 51 19 06 29 1F 06 51 19 06 29 1F 06 51 19 06 29 1F 06 51 19
					/*VESA optimize*/
					39 00 00 40 00 00 06 F0 55 AA 52 08 00
					39 00 00 40 00 00 02 E0 1C
					39 00 00 40 00 00 05 FF AA 55 A5 80
					39 00 00 40 00 00 02 6F 31
					39 00 00 00 00 00 03 F8 01 8E
					39 00 00 40 00 00 05 FF AA 55 A5 80
					39 00 00 40 00 00 02 6F 15
					39 00 00 40 00 00 03 F8 01 8D
					39 00 00 40 00 00 02 6F 16
					39 00 00 40 00 00 03 F4 02 74
					39 00 00 40 00 00 05 FF AA 55 A5 81
					39 00 00 40 00 00 02 6F 05
					39 00 00 40 00 00 03 FE 3C 3C
					39 00 00 40 00 00 02 6F 0D
					39 00 00 00 00 00 02 FB 80
					39 00 00 40 00 00 05 FF AA 55 A5 80
					39 00 00 40 00 00 02 6F 0A
					39 00 00 40 00 00 06 F6 70 70 70 70 70
					39 00 00 40 00 00 02 17 30
					//Source optimize
					39 00 00 40 00 00 05 FF AA 55 A5 80
					39 00 00 40 00 00 02 6F 2A
					39 00 00 40 00 00 02 F4 08
					//MIPI RX driving optimize
					39 00 00 40 00 00 05 FF AA 55 A5 82
					39 00 00 40 00 00 02 6F 09
					39 00 00 40 00 00 02 F2 FF
					39 00 00 40 00 00 06 F0 55 AA 52 08 01
					39 00 00 40 00 00 02 6F 06
					39 00 00 40 00 00 03 C5 0A 0A
					//close cmd2 cmd3
					39 00 00 40 00 00 06 F0 55 AA 52 00 00
					39 00 00 40 00 00 05 FF AA 55 A5 00
					39 00 00 40 00 00 05 2A 00 00 04 C7
					39 00 00 40 00 00 05 2B 00 00 0B 5F
					39 00 00 40 00 00 02 90 03
					39 00 00 40 00 00 02 6F 01
					39 00 00 40 00 00 02 90 43
					39 00 00 40 00 00 13 91 AB A8 00 20 C2 00 02 32 03 47 00 08 03 19 02 CE 10 F0
					39 00 00 40 00 00 02 6F 06
					39 00 00 40 00 00 02 6D 00
					/*1hz*/
					39 00 00 40 00 00 02 6D 09
					39 00 00 40 00 00 02 2F 30
					/*gir on*/
					39 00 00 40 00 00 02 5F 00
					39 00 00 40 00 00 02 35 00
					39 00 00 40 00 00 03 51 00 00
					39 00 00 40 00 00 02 53 20
					39 00 00 00 00 00 02 26 00
					39 00 00 00 00 00 02 5A 00
					/* Display On */
					05 00 00 00 78 00 01 11
					05 00 00 00 00 00 01 29
				];
				qcom,mdss-dsi-on-command-state = "dsi_lp_mode";

				qcom,mdss-dsi-timing-switch-command = [
					/* Auto Dimming OFF */
					/*Frame skip OFF (Auto Mode)*/
					/*Frame Skip Mode 1*/
					39 00 00 40 00 00 06 F0 55 AA 52 08 00
					//AUTO ENABLE
					39 00 00 40 00 00 02 6F D9
					39 00 00 40 00 00 02 BA 00
					//OPT_fskip_abort_event ON
					/*backlight enable the back fun*/
					39 00 00 40 00 00 02 6F 08
					39 00 00 40 00 00 02 B2 C0
					//close cmd2
					39 00 00 40 00 00 06 F0 55 AA 52 00 00
					/* Frequency Select 1Hz */
					39 00 00 40 00 00 02 6F 03
					39 00 00 40 00 00 03 35 00 00
					39 00 00 00 00 00 02 6D 09
				];

				qcom,mdss-dsi-timing-switch-command-state = "dsi_lp_mode";

				qcom,mdss-dsi-nolp-command = [
					39 00 00 00 00 00 03 51 00 00
					/* Aod Mode Off */
					39 00 00 40 00 00 02 38 00
					/*back to normal te*/
					39 00 00 40 00 00 02 6F 03
					39 00 00 00 00 00 03 35 00 00
				];
				qcom,mdss-dsi-nolp-command-update = <0x51 0 2>;
				qcom,mdss-dsi-nolp-command-state = "dsi_hs_mode";
			};
			timing@9 {
				#include "dsi-panel-n8-42-02-0a-prim-dsc-cmd-common.dtsi"
				cell-index = <9>;
				qcom,mdss-dsi-panel-framerate = <120>;
				/* ---------------------------- */
				/* | 15 - 14 | 13 - 7 | 6 - 0 | */
				/* ---------------------------- */
				/* |   mode  | sf fps | min fps| */
				/* ---------------------------- -*/
				/* mode: 1 idle, 2 auto, 3 qsync */
				/*   2 << 14 | 120 << 7 | 10      */
				qcom,mdss-dsi-h-sync-skew = <48138>;
				/* mode: 0 normal, 1 idle, 2 auto, 3 qsync, 4 diff, 5 test */
				mi,mdss-dsi-ddic-mode = "auto";
				mi,mdss-dsi-sf-framerate = <120>;
				mi,mdss-dsi-ddic-min-framerate = <10>;

				qcom,mdss-dsi-on-command = [
					/* Low frame switch skip 120 TE */
					39 00 00 40 00 00 06 F0 55 AA 52 08 03
					39 00 00 40 00 00 02 6F 0B
					39 00 00 00 00 00 02 C6 06
					/*IDLE 1*/
					39 00 00 40 00 00 06 F0 55 AA 52 08 00
					39 00 00 40 00 00 02 6F A4
					39 00 00 40 00 00 11 BA 03 03 03 06 01 01 01 06 00 01 01 14 00 00 01 16
					39 00 00 40 00 00 02 6F 1C
					39 00 00 40 00 00 11 BA 01 01 01 01 00 00 00 00 01 01 01 01 00 00 00 00
					39 00 00 40 00 00 02 6F 2C
					39 00 00 40 00 00 11 BA 01 01 01 01 01 01 01 01 01 01 01 01 00 00 00 00
					39 00 00 40 00 00 02 6F 3C
					39 00 00 40 00 00 11 BA 01 01 01 01 03 03 03 03 01 01 01 01 00 00 00 00
					39 00 00 40 00 00 02 6F 4C
					39 00 00 40 00 00 11 BA 01 01 01 01 0B 0B 04 0B 01 01 01 01 00 00 00 00
					/*thermal compensation DBI on*/
					39 00 00 40 00 00 06 F0 55 AA 52 08 08
					39 00 00 40 00 00 03 C2 22 80
					39 00 00 40 00 00 02 C7 13
					39 00 00 40 00 00 13 CB 00 00 00 00 00 00 00 00 00 00 00 00 00 00 00 00 00 00
					39 00 00 40 00 00 13 CC 00 00 00 00 00 00 00 00 00 00 00 00 00 00 00 00 00 00
					39 00 00 40 00 00 13 CE 00 00 00 00 00 00 00 00 00 00 00 00 00 00 00 00 00 00
					39 00 00 40 00 00 03 D3 80 01
					39 00 00 40 00 00 02 6F 02
					39 00 00 40 00 00 06 D3 10 00 98 00 6B
					39 00 00 00 00 00 05 67 80 40 80 80
					/*on ddic corner*/
					39 00 00 40 00 00 06 F0 55 AA 52 08 07
					39 00 00 40 00 00 02 6F 03
					39 00 00 40 00 00 05 C0 00 00 00 00
					39 00 00 40 00 00 16 C1 30 0F 02 71 09 61 F6 6E 3F FD BA F2 3F F9 AE 9E 00 00 89 54 40
					39 00 00 40 00 00 02 6F 15
					39 00 00 40 00 00 11 C1 0F 00 37 AF 00 00 19 37 F0 E7 89 0B 9F 30 FF 00
					39 00 00 40 00 00 02 6F 25
					39 00 00 40 00 00 08 C1 00 2F 37 00 10 18 00
					39 00 00 40 00 00 16 C2 30 0F 27 10 00 64 F8 30 3F FA AA 38 3F FF 84 90 00 00 27 10 00
					39 00 00 40 00 00 02 6F 15
					39 00 00 40 00 00 11 C2 03 00 00 0A 00 56 F6 B3 F0 62 F6 06 2C C0 00 FE
					39 00 00 40 00 00 02 6F 25
					39 00 00 40 00 00 08 C2 00 01 09 00 4F 56 00
					39 00 00 00 00 00 16 C3 30 0F 01 69 01 21 FD 7A 3F FE 6A 5A 3F FE C1 F2 00 00 3C C7 39
					39 00 00 40 00 00 02 6F 15
					39 00 00 40 00 00 11 C3 0C 00 0A 36 00 19 55 44 F0 C5 D5 09 E9 F0 FF FF
					39 00 00 40 00 00 02 6F 25
					39 00 00 40 00 00 08 C3 44 91 99 00 10 18 00
					39 00 00 40 00 00 16 C4 3C 00 2F 44 00 64 08 98 3F F5 0A 60 00 00 00 00 00 00 00 00 00
					39 00 00 40 00 00 02 6F 15
					39 00 00 40 00 00 11 C4 99 00 00 0A AB 69 09 B3 C0 62 0A 00 00 00 00 00
					39 00 00 40 00 00 02 6F 25
					39 00 00 40 00 00 08 C4 44 BF C7 00 4F 57 00
					39 00 00 40 00 00 16 C5 3C 00 01 69 01 21 02 86 3F FD D5 78 00 00 B8 D8 00 00 02 2B F1
					39 00 00 40 00 00 02 6F 15
					39 00 00 40 00 00 11 C5 2E 00 0A 36 BB 0A 46 44 C0 C5 2B 00 00 30 FF 00
					39 00 00 40 00 00 02 6F 25
					39 00 00 40 00 00 08 C5 00 2F 37 BB 47 4F 00
					39 00 00 00 00 00 16 C6 3C 00 02 71 0B 64 0A 8C 3F FC 9A DC 00 04 C0 CC 00 00 03 67 95
					39 00 00 40 00 00 02 6F 15
					39 00 00 40 00 00 11 C6 09 00 37 B4 BB 46 5F 37 C0 E7 7C 00 00 30 FF 00
					39 00 00 40 00 00 02 6F 25
					39 00 00 00 00 00 08 C6 00 01 09 BB 07 0F 00
					39 00 00 40 00 00 16 C7 31 00 06 E4 06 E4 00 00 3F FD BD 30 3F FD BD 30 00 00 34 0E 78
					39 00 00 40 00 00 02 6F 15
					39 00 00 40 00 00 11 C7 0C 22 38 63 00 23 4E 44 F0 D6 D6 06 E4 F0 FF FF
					39 00 00 40 00 00 02 6F 25
					39 00 00 40 00 00 08 C7 44 91 99 BB 47 4F 00
					39 00 00 40 00 00 16 C8 3D 00 06 E4 06 E4 00 00 3F FD BD 30 00 00 00 00 00 00 02 49 B4
					39 00 00 40 00 00 02 6F 15
					39 00 00 00 00 00 11 C8 1D 22 38 63 00 4F 7A 44 C0 D6 2A 00 00 30 FF 00
					39 00 00 40 00 00 02 6F 25
					39 00 00 40 00 00 08 C8 44 BF C7 BB 07 0F 00
					39 00 00 40 00 00 0F D1 80 00 00 00 00 04 C7 80 00 01 94 B0 04 C7
					39 00 00 40 00 00 02 6F 0E
					39 00 00 40 00 00 0F D1 80 00 01 AB B1 04 C7 FF FF A4 DE 50 04 C7
					39 00 00 40 00 00 02 6F 1C
					39 00 00 40 00 00 0F D1 FF FF AD 0A 89 04 C7 FF FE ED A5 A0 04 C7
					39 00 00 40 00 00 02 6F 2A
					39 00 00 40 00 00 0C D1 80 00 02 49 B4 04 C7 FF FF D0 84
					39 00 00 00 00 00 12 D2 F0 04 C7 00 00 00 00 00 00 00 00 00 00 00 00 00 00
					/*backlight*/
					39 00 00 40 00 00 06 F0 55 AA 52 08 00
					39 00 00 40 00 00 02 6F 08
					//OPT_fskip_abort_event
					39 00 00 40 00 00 02 B2 C0
					//ESD DECTED
					39 00 00 40 00 00 06 F0 55 AA 52 08 00
					39 00 00 40 00 00 03 BE 47 45
					//normal low,active high
					39 00 00 40 00 00 02 6F 05
					39 00 00 40 00 00 02 BE 28
					39 00 00 40 00 00 02 6F 19
					39 00 00 40 00 00 05 BE 10 91 00 AB
					//VESA_PPS_DT_BLOCK_SLO_DISPON=1
					39 00 00 40 00 00 02 6F 0D
					39 00 00 40 00 00 02 D8 42
					//AUTO ENABLE
					39 00 00 40 00 00 06 F0 55 AA 52 08 00
					39 00 00 40 00 00 02 6F D9
					39 00 00 40 00 00 02 BA 00
					//DVDD enhance
					39 00 00 40 00 00 06 F0 55 AA 52 08 01
					39 00 00 40 00 00 02 6F 05
					39 00 00 40 00 00 04 C5 00 00 00
					//EM pulse multi to one optimize
					39 00 00 40 00 00 02 E5 00
					//VINITN2 bias adjust
					39 00 00 40 00 00 05 FF AA 55 A5 80
					39 00 00 40 00 00 02 6F 32
					39 00 00 40 00 00 02 F9 00
					//AOD WB timing optimize
					39 00 00 40 00 00 05 FF AA 55 A5 81
					39 00 00 40 00 00 02 6F 02
					39 00 00 40 00 00 02 F9 84
					//AOD SOP optimize
					39 00 00 40 00 00 05 FF AA 55 A5 81
					39 00 00 40 00 00 02 6F 13
					39 00 00 40 00 00 02 F9 00
					//Enalbe fskip_extend vfp function
					39 00 00 40 00 00 05 FF AA 55 A5 81
					39 00 00 40 00 00 02 6F 0C
					39 00 00 40 00 00 02 FD 08
					//Frameskip Chopper timing adjust
					39 00 00 40 00 00 05 FF AA 55 A5 81
					39 00 00 40 00 00 02 6F 10
					39 00 00 40 00 00 02 FB 40
					//Disable VOLTP output for power saving
					39 00 00 40 00 00 05 FF AA 55 A5 80
					39 00 00 40 00 00 02 6F 42
					39 00 00 40 00 00 02 F4 00
					39 00 00 40 00 00 02 6F 49
					39 00 00 00 00 00 02 F2 10
					/*video trim*/
					39 00 00 40 00 00 06 F0 55 AA 52 08 01
					39 00 00 40 00 00 2A C3 DD 06 20 11 FF 00 06 20 11 FF 00 06 29 1F 06 51 19 06 29 1F 06 51 19 06 29 1F 06 51 19 06 29 1F 06 51 19 06 29 1F 06 51 19
					/*VESA optimize*/
					39 00 00 40 00 00 06 F0 55 AA 52 08 00
					39 00 00 40 00 00 02 E0 1C
					39 00 00 40 00 00 05 FF AA 55 A5 80
					39 00 00 40 00 00 02 6F 31
					39 00 00 00 00 00 03 F8 01 8E
					39 00 00 40 00 00 05 FF AA 55 A5 80
					39 00 00 40 00 00 02 6F 15
					39 00 00 40 00 00 03 F8 01 8D
					39 00 00 40 00 00 02 6F 16
					39 00 00 40 00 00 03 F4 02 74
					39 00 00 40 00 00 05 FF AA 55 A5 81
					39 00 00 40 00 00 02 6F 05
					39 00 00 40 00 00 03 FE 3C 3C
					39 00 00 40 00 00 02 6F 0D
					39 00 00 00 00 00 02 FB 80
					39 00 00 40 00 00 05 FF AA 55 A5 80
					39 00 00 40 00 00 02 6F 0A
					39 00 00 40 00 00 06 F6 70 70 70 70 70
					39 00 00 40 00 00 02 17 30
					//Source optimize
					39 00 00 40 00 00 05 FF AA 55 A5 80
					39 00 00 40 00 00 02 6F 2A
					39 00 00 40 00 00 02 F4 08
					//MIPI RX driving optimize
					39 00 00 40 00 00 05 FF AA 55 A5 82
					39 00 00 40 00 00 02 6F 09
					39 00 00 40 00 00 02 F2 FF
					39 00 00 40 00 00 06 F0 55 AA 52 08 01
					39 00 00 40 00 00 02 6F 06
					39 00 00 40 00 00 03 C5 0A 0A
					//close cmd2 cmd3
					39 00 00 40 00 00 06 F0 55 AA 52 00 00
					39 00 00 40 00 00 05 FF AA 55 A5 00
					39 00 00 40 00 00 05 2A 00 00 04 C7
					39 00 00 40 00 00 05 2B 00 00 0B 5F
					39 00 00 40 00 00 02 90 03
					39 00 00 40 00 00 02 6F 01
					39 00 00 40 00 00 02 90 43
					39 00 00 40 00 00 13 91 AB A8 00 20 C2 00 02 32 03 47 00 08 03 19 02 CE 10 F0
					39 00 00 40 00 00 02 6F 06
					39 00 00 40 00 00 02 6D 00
					/*10hz*/
					39 00 00 40 00 00 02 6D 08
					39 00 00 40 00 00 02 2F 30
					/*gir on*/
					39 00 00 40 00 00 02 5F 00
					39 00 00 40 00 00 02 35 00
					39 00 00 40 00 00 03 51 00 00
					39 00 00 40 00 00 02 53 20
					39 00 00 00 00 00 02 26 00
					39 00 00 00 00 00 02 5A 00
					/* Display On */
					05 00 00 00 78 00 01 11
					05 00 00 00 00 00 01 29
				];
				qcom,mdss-dsi-on-command-state = "dsi_lp_mode";

				qcom,mdss-dsi-timing-switch-command = [
					/* Auto Dimming OFF */
					/*Frame skip OFF (Auto Mode)*/
					/*Frame Skip Mode 1*/
					39 00 00 40 00 00 06 F0 55 AA 52 08 00
					//AUTO ENABLE
					39 00 00 40 00 00 02 6F D9
					39 00 00 40 00 00 02 BA 00
					//OPT_fskip_abort_event ON
					/*backlight enable the back fun*/
					39 00 00 40 00 00 02 6F 08
					39 00 00 40 00 00 02 B2 C0
					//close cmd2
					39 00 00 40 00 00 06 F0 55 AA 52 00 00
					/* Frequency Select 10Hz */
					39 00 00 40 00 00 02 6F 03
					39 00 00 40 00 00 03 35 00 00
					39 00 00 00 00 00 02 6D 08
				];

				qcom,mdss-dsi-timing-switch-command-state = "dsi_lp_mode";

				qcom,mdss-dsi-nolp-command = [
					39 00 00 00 00 00 03 51 00 00
					/* Aod Mode Off */
					39 00 00 40 00 00 02 38 00
					/*back to normal te*/
					39 00 00 40 00 00 02 6F 03
					39 00 00 00 00 00 03 35 00 00
				];
				qcom,mdss-dsi-nolp-command-update = <0x51 0 2>;
				qcom,mdss-dsi-nolp-command-state = "dsi_hs_mode";
			};
			timing@10 {
				#include "dsi-panel-n8-42-02-0a-prim-dsc-cmd-common.dtsi"
				cell-index = <10>;
				qcom,mdss-dsi-panel-framerate = <120>;
				/* ---------------------------- */
				/* | 15 - 14 | 13 - 7 | 6 - 0 | */
				/* ---------------------------- */
				/* |   mode  | sf fps | min fps| */
				/* ---------------------------- -*/
				/* mode: 1 idle, 2 auto, 3 qsync */
				/*   1 << 14 | 120 << 7 | 127(0.5HZ)      */
				qcom,mdss-dsi-h-sync-skew = <31871>;
				/* mode: 0 normal, 1 idle, 2 auto, 3 qsync, 4 diff, 5 test */
				mi,mdss-dsi-ddic-mode = "test";
				mi,mdss-dsi-sf-framerate = <120>;
				mi,mdss-dsi-ddic-min-framerate = <127>;
				qcom,mdss-dsi-on-command = [
					/* Low frame switch skip 120 TE */
					39 00 00 40 00 00 06 F0 55 AA 52 08 03
					39 00 00 40 00 00 02 6F 0B
					39 00 00 00 00 00 02 C6 06
					/*IDLE 1*/
					39 00 00 40 00 00 06 F0 55 AA 52 08 00
					39 00 00 40 00 00 02 6F A4
					39 00 00 40 00 00 11 BA 03 03 03 06 01 01 01 06 00 01 01 14 00 00 01 16
					39 00 00 40 00 00 02 6F 1C
					39 00 00 40 00 00 11 BA 01 01 01 01 00 00 00 00 01 01 01 01 00 00 00 00
					39 00 00 40 00 00 02 6F 2C
					39 00 00 40 00 00 11 BA 01 01 01 01 01 01 01 01 01 01 01 01 00 00 00 00
					39 00 00 40 00 00 02 6F 3C
					39 00 00 40 00 00 11 BA 01 01 01 01 03 03 03 03 01 01 01 01 00 00 00 00
					39 00 00 40 00 00 02 6F 4C
					39 00 00 40 00 00 11 BA 01 01 01 01 0B 0B 04 0B 01 01 01 01 00 00 00 00
					/*thermal compensation DBI on*/
					39 00 00 40 00 00 06 F0 55 AA 52 08 08
					39 00 00 40 00 00 03 C2 22 80
					39 00 00 40 00 00 02 C7 13
					39 00 00 40 00 00 13 CB 00 00 00 00 00 00 00 00 00 00 00 00 00 00 00 00 00 00
					39 00 00 40 00 00 13 CC 00 00 00 00 00 00 00 00 00 00 00 00 00 00 00 00 00 00
					39 00 00 40 00 00 13 CE 00 00 00 00 00 00 00 00 00 00 00 00 00 00 00 00 00 00
					39 00 00 40 00 00 03 D3 80 01
					39 00 00 40 00 00 02 6F 02
					39 00 00 40 00 00 06 D3 10 00 98 00 6B
					39 00 00 00 00 00 05 67 80 40 80 80
					/*on ddic corner*/
					39 00 00 40 00 00 06 F0 55 AA 52 08 07
					39 00 00 40 00 00 02 6F 03
					39 00 00 40 00 00 05 C0 00 00 00 00
					39 00 00 40 00 00 16 C1 30 0F 02 71 09 61 F6 6E 3F FD BA F2 3F F9 AE 9E 00 00 89 54 40
					39 00 00 40 00 00 02 6F 15
					39 00 00 40 00 00 11 C1 0F 00 37 AF 00 00 19 37 F0 E7 89 0B 9F 30 FF 00
					39 00 00 40 00 00 02 6F 25
					39 00 00 40 00 00 08 C1 00 2F 37 00 10 18 00
					39 00 00 40 00 00 16 C2 30 0F 27 10 00 64 F8 30 3F FA AA 38 3F FF 84 90 00 00 27 10 00
					39 00 00 40 00 00 02 6F 15
					39 00 00 40 00 00 11 C2 03 00 00 0A 00 56 F6 B3 F0 62 F6 06 2C C0 00 FE
					39 00 00 40 00 00 02 6F 25
					39 00 00 40 00 00 08 C2 00 01 09 00 4F 56 00
					39 00 00 00 00 00 16 C3 30 0F 01 69 01 21 FD 7A 3F FE 6A 5A 3F FE C1 F2 00 00 3C C7 39
					39 00 00 40 00 00 02 6F 15
					39 00 00 40 00 00 11 C3 0C 00 0A 36 00 19 55 44 F0 C5 D5 09 E9 F0 FF FF
					39 00 00 40 00 00 02 6F 25
					39 00 00 40 00 00 08 C3 44 91 99 00 10 18 00
					39 00 00 40 00 00 16 C4 3C 00 2F 44 00 64 08 98 3F F5 0A 60 00 00 00 00 00 00 00 00 00
					39 00 00 40 00 00 02 6F 15
					39 00 00 40 00 00 11 C4 99 00 00 0A AB 69 09 B3 C0 62 0A 00 00 00 00 00
					39 00 00 40 00 00 02 6F 25
					39 00 00 40 00 00 08 C4 44 BF C7 00 4F 57 00
					39 00 00 40 00 00 16 C5 3C 00 01 69 01 21 02 86 3F FD D5 78 00 00 B8 D8 00 00 02 2B F1
					39 00 00 40 00 00 02 6F 15
					39 00 00 40 00 00 11 C5 2E 00 0A 36 BB 0A 46 44 C0 C5 2B 00 00 30 FF 00
					39 00 00 40 00 00 02 6F 25
					39 00 00 40 00 00 08 C5 00 2F 37 BB 47 4F 00
					39 00 00 00 00 00 16 C6 3C 00 02 71 0B 64 0A 8C 3F FC 9A DC 00 04 C0 CC 00 00 03 67 95
					39 00 00 40 00 00 02 6F 15
					39 00 00 40 00 00 11 C6 09 00 37 B4 BB 46 5F 37 C0 E7 7C 00 00 30 FF 00
					39 00 00 40 00 00 02 6F 25
					39 00 00 00 00 00 08 C6 00 01 09 BB 07 0F 00
					39 00 00 40 00 00 16 C7 31 00 06 E4 06 E4 00 00 3F FD BD 30 3F FD BD 30 00 00 34 0E 78
					39 00 00 40 00 00 02 6F 15
					39 00 00 40 00 00 11 C7 0C 22 38 63 00 23 4E 44 F0 D6 D6 06 E4 F0 FF FF
					39 00 00 40 00 00 02 6F 25
					39 00 00 40 00 00 08 C7 44 91 99 BB 47 4F 00
					39 00 00 40 00 00 16 C8 3D 00 06 E4 06 E4 00 00 3F FD BD 30 00 00 00 00 00 00 02 49 B4
					39 00 00 40 00 00 02 6F 15
					39 00 00 00 00 00 11 C8 1D 22 38 63 00 4F 7A 44 C0 D6 2A 00 00 30 FF 00
					39 00 00 40 00 00 02 6F 25
					39 00 00 40 00 00 08 C8 44 BF C7 BB 07 0F 00
					39 00 00 40 00 00 0F D1 80 00 00 00 00 04 C7 80 00 01 94 B0 04 C7
					39 00 00 40 00 00 02 6F 0E
					39 00 00 40 00 00 0F D1 80 00 01 AB B1 04 C7 FF FF A4 DE 50 04 C7
					39 00 00 40 00 00 02 6F 1C
					39 00 00 40 00 00 0F D1 FF FF AD 0A 89 04 C7 FF FE ED A5 A0 04 C7
					39 00 00 40 00 00 02 6F 2A
					39 00 00 40 00 00 0C D1 80 00 02 49 B4 04 C7 FF FF D0 84
					39 00 00 00 00 00 12 D2 F0 04 C7 00 00 00 00 00 00 00 00 00 00 00 00 00 00
					//ESD DECTED
					39 00 00 40 00 00 06 F0 55 AA 52 08 00
					39 00 00 40 00 00 03 BE 47 45
					//normal low,active high
					39 00 00 40 00 00 02 6F 05
					39 00 00 40 00 00 02 BE 28
					39 00 00 40 00 00 02 6F 19
					39 00 00 40 00 00 05 BE 10 91 00 AB
					//VESA_PPS_DT_BLOCK_SLO_DISPON=1
					39 00 00 40 00 00 02 6F 0D
					39 00 00 40 00 00 02 D8 42
					//AUTO ENABLE
					39 00 00 40 00 00 06 F0 55 AA 52 08 00
					39 00 00 40 00 00 02 6F D9
					39 00 00 40 00 00 02 BA 00
					//DVDD enhance
					39 00 00 40 00 00 06 F0 55 AA 52 08 01
					39 00 00 40 00 00 02 6F 05
					39 00 00 40 00 00 04 C5 00 00 00
					//EM pulse multi to one optimize
					39 00 00 40 00 00 02 E5 00
					//VINITN2 bias adjust
					39 00 00 40 00 00 05 FF AA 55 A5 80
					39 00 00 40 00 00 02 6F 32
					39 00 00 40 00 00 02 F9 00
					//AOD WB timing optimize
					39 00 00 40 00 00 05 FF AA 55 A5 81
					39 00 00 40 00 00 02 6F 02
					39 00 00 40 00 00 02 F9 84
					//AOD SOP optimize
					39 00 00 40 00 00 05 FF AA 55 A5 81
					39 00 00 40 00 00 02 6F 13
					39 00 00 40 00 00 02 F9 00
					//Enalbe fskip_extend vfp function
					39 00 00 40 00 00 05 FF AA 55 A5 81
					39 00 00 40 00 00 02 6F 0C
					39 00 00 40 00 00 02 FD 08
					//Frameskip Chopper timing adjust
					39 00 00 40 00 00 05 FF AA 55 A5 81
					39 00 00 40 00 00 02 6F 10
					39 00 00 40 00 00 02 FB 40
					//Disable VOLTP output for power saving
					39 00 00 40 00 00 05 FF AA 55 A5 80
					39 00 00 40 00 00 02 6F 42
					39 00 00 40 00 00 02 F4 00
					39 00 00 40 00 00 02 6F 49
					39 00 00 00 00 00 02 F2 10
					/*video trim*/
					39 00 00 40 00 00 06 F0 55 AA 52 08 01
					39 00 00 40 00 00 2A C3 DD 06 20 11 FF 00 06 20 11 FF 00 06 29 1F 06 51 19 06 29 1F 06 51 19 06 29 1F 06 51 19 06 29 1F 06 51 19 06 29 1F 06 51 19
					39 00 00 40 00 00 06 F0 55 AA 52 08 00
					39 00 00 40 00 00 02 E0 1C
					39 00 00 40 00 00 05 FF AA 55 A5 80
					39 00 00 40 00 00 02 6F 31
					39 00 00 00 00 00 03 F8 01 8E
					39 00 00 40 00 00 05 FF AA 55 A5 80
					39 00 00 40 00 00 02 6F 15
					39 00 00 40 00 00 03 F8 01 8D
					39 00 00 40 00 00 02 6F 16
					39 00 00 40 00 00 03 F4 02 74
					39 00 00 40 00 00 05 FF AA 55 A5 81
					39 00 00 40 00 00 02 6F 05
					39 00 00 40 00 00 03 FE 3C 3C
					39 00 00 40 00 00 02 6F 0D
					39 00 00 00 00 00 02 FB 80
					39 00 00 40 00 00 05 FF AA 55 A5 80
					39 00 00 40 00 00 02 6F 0A
					39 00 00 40 00 00 06 F6 70 70 70 70 70
					39 00 00 40 00 00 02 17 30
					//Source optimize
					39 00 00 40 00 00 05 FF AA 55 A5 80
					39 00 00 40 00 00 02 6F 2A
					39 00 00 40 00 00 02 F4 08
					//MIPI RX driving optimize
					39 00 00 40 00 00 05 FF AA 55 A5 82
					39 00 00 40 00 00 02 6F 09
					39 00 00 40 00 00 02 F2 FF
					39 00 00 40 00 00 06 F0 55 AA 52 08 01
					39 00 00 40 00 00 02 6F 06
					39 00 00 40 00 00 03 C5 0A 0A
					39 00 00 40 00 00 05 2A 00 00 04 C7
					39 00 00 40 00 00 05 2B 00 00 0B 5F
					39 00 00 40 00 00 02 90 03
					39 00 00 40 00 00 02 6F 01
					39 00 00 40 00 00 02 90 43
					39 00 00 40 00 00 13 91 AB A8 00 20 C2 00 02 32 03 47 00 08 03 19 02 CE 10 F0
					39 00 00 40 00 00 02 6F 06
					39 00 00 40 00 00 02 6D 00
					39 00 00 40 00 00 06 F0 55 AA 52 08 00
					39 00 00 40 00 00 02 6F 66
					39 00 00 40 00 00 02 BA 01
					39 00 00 40 00 00 02 6F 8E
					39 00 00 40 00 00 02 BA 01
					39 00 00 40 00 00 02 6F 7E
					39 00 00 40 00 00 02 BA EF
					//close cmd2 cmd3
					39 00 00 40 00 00 06 F0 55 AA 52 00 00
					39 00 00 40 00 00 05 FF AA 55 A5 00
					/*0.5hz*/
					39 00 00 40 00 00 02 6D 0A
					39 00 00 40 00 00 02 2F 30
					/*gir on*/
					39 00 00 40 00 00 02 5F 00
					39 00 00 40 00 00 02 35 00
					39 00 00 40 00 00 03 51 00 00
					39 00 00 40 00 00 02 53 20
					39 00 00 00 00 00 02 26 00
					39 00 00 00 00 00 02 5A 00
					/* Display On */
					05 00 00 00 78 00 01 11
					05 00 00 00 00 00 01 29
				];
				qcom,mdss-dsi-on-command-state = "dsi_lp_mode";

				qcom,mdss-dsi-timing-switch-command = [
					/* Auto Dimming OFF */
					/*Frame skip OFF (test Mode)*/
					/*Frame Skip Mode 1*/
					/*backlight off the back fun*/
					39 00 00 40 00 00 06 F0 55 AA 52 08 00
					//AUTO ENABLE
					39 00 00 40 00 00 02 6F D9
					39 00 00 40 00 00 02 BA 00
					39 00 00 40 00 00 02 6F 08
					39 00 00 40 00 00 02 B2 80
					/* Frequency Select 0.5Hz */
					39 00 00 40 00 00 06 F0 55 AA 52 08 00
					39 00 00 40 00 00 02 6F 66
					39 00 00 40 00 00 02 BA 01
					39 00 00 40 00 00 02 6F 8E
					39 00 00 40 00 00 02 BA 01
					39 00 00 40 00 00 02 6F 7E
					39 00 00 40 00 00 02 BA EF
					//close cmd2
					39 00 00 40 00 00 06 F0 55 AA 52 00 00
					39 00 00 40 00 00 02 2F 30
					39 00 00 00 00 00 02 6D 0A
				];

				qcom,mdss-dsi-timing-switch-command-state = "dsi_lp_mode";

				qcom,mdss-dsi-nolp-command = [
					39 00 00 00 00 00 03 51 00 00
					/* Aod Mode Off */
					39 00 00 40 00 00 02 38 00
					/*back to normal te*/
					39 00 00 40 00 00 02 6F 03
					39 00 00 00 00 00 03 35 00 00
				];
				qcom,mdss-dsi-nolp-command-update = <0x51 0 2>;
				qcom,mdss-dsi-nolp-command-state = "dsi_hs_mode";
			};
		};
	};
};

&dsi_n8_42_02_0a_prim_dsc_cmd {
	qcom,panel-supply-entries = <&dsi_panel_pwr_supply_prim_N8>;
	qcom,mdss-dsi-bl-pmic-control-type = "bl_ctrl_dcs";
	qcom,mdss-dsi-bl-min-level = <15>;
	qcom,mdss-dsi-bl-max-level = <16383>;
	qcom,bl-dsc-cmd-state = "dsi_hs_mode";
	qcom,mdss-brightness-max-level = <16383>;
	qcom,mdss-brightness-init-level = <307>;
	qcom,platform-reset-gpio = <&tlmm 133 0>;

	mi,panel-build-id-read-needed;
	mi,panel-build-id-read-length = <1>;
	mi,mdss-dsi-panel-build-id-read-command = [06 01 00 01 00 00 01 DA];
	mi,mdss-dsi-panel-build-id-read-command-state = "dsi_hs_mode";

	mi,disable-ic-dimming-flag;
	qcom,mdss-dsi-panel-vsync-delay;
	qcom,ulps-enabled;
	qcom,dsi-select-clocks = "pll_byte_clk0", "pll_dsi_clk0";
	qcom,mdss-dsi-clk-strength = <0xFF>;
};
